[part 1 of 2: package /STELLANTIS/EPT/ASWCs]
AUTOSAR XML (schema 4-2-2)
package /STELLANTIS/EPT/ASWCs
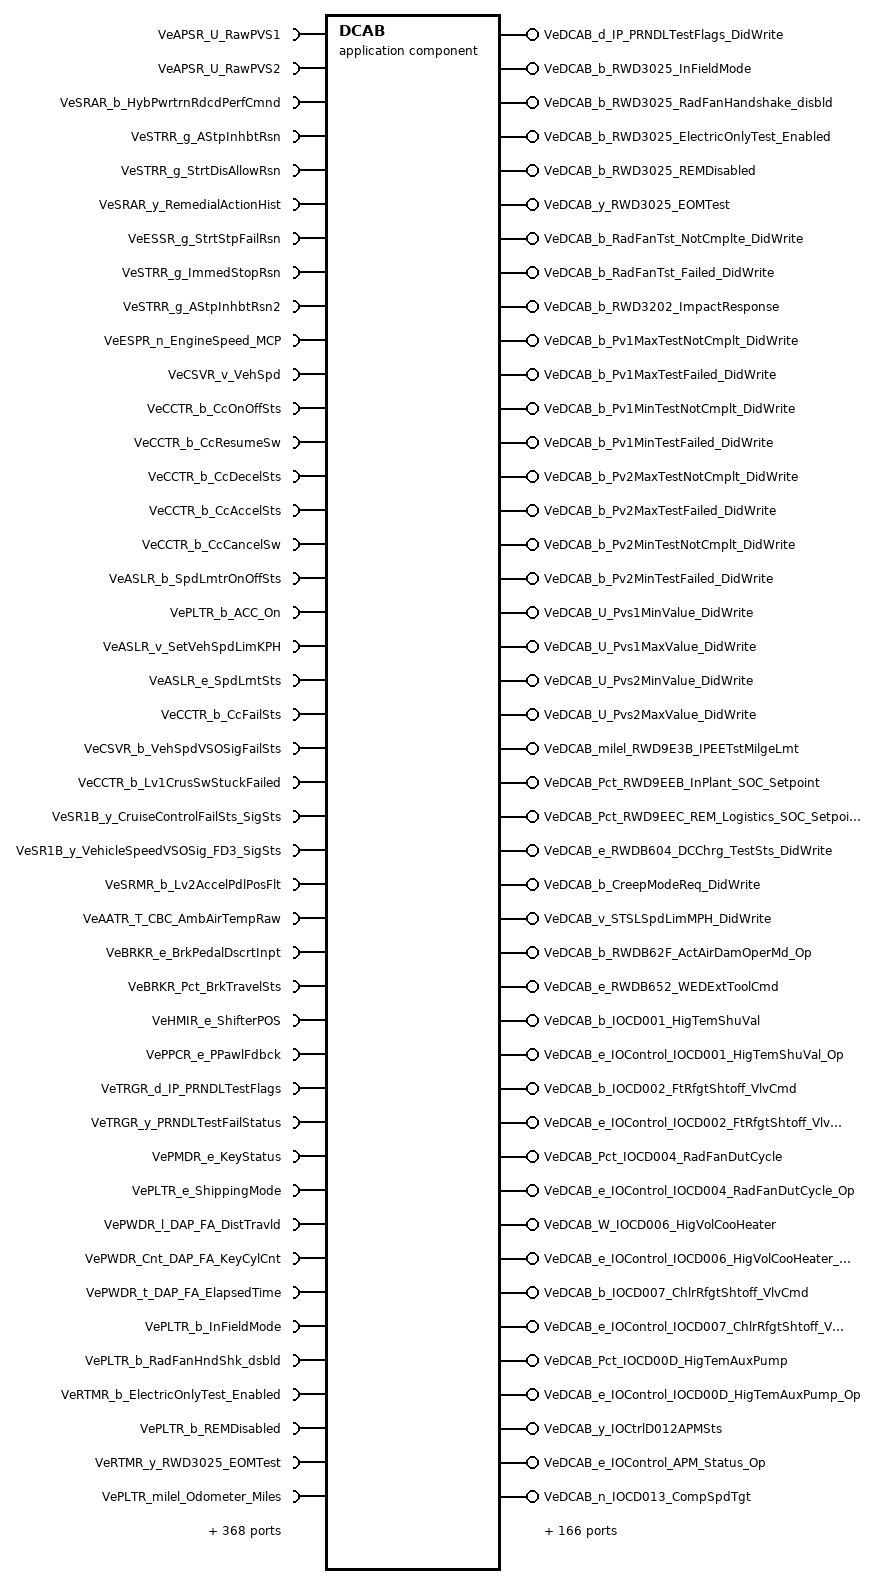
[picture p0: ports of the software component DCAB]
  application sw component type DCAB
    429 x require port:
      VeAPSR_U_RawPVS1: nonqueued-receiver-com-spec{data-element=Value, init-value=0}, required-interface=VeAPSR_U_RawPVS1
      VeAPSR_U_RawPVS2: nonqueued-receiver-com-spec{data-element=Value, init-value=0}, required-interface=VeAPSR_U_RawPVS2
      VeSRAR_b_HybPwrtrnRdcdPerfCmnd: nonqueued-receiver-com-spec{data-element=Value, init-value=0}, required-interface=VeSRAR_b_HybPwrtrnRdcdPerfCmnd
      VeSTRR_g_AStpInhbtRsn: nonqueued-receiver-com-spec{data-element=Value, init-value=0}, required-interface=VeSTRR_g_AStpInhbtRsn
      VeSTRR_g_StrtDisAllowRsn: nonqueued-receiver-com-spec{data-element=Value, init-value=0}, required-interface=VeSTRR_g_StrtDisAllowRsn
      VeSRAR_y_RemedialActionHist: nonqueued-receiver-com-spec{data-element=Value, init-value=0}, required-interface=VeSRAR_y_RemedialActionHist
      VeESSR_g_StrtStpFailRsn: nonqueued-receiver-com-spec{data-element=Value, init-value=0}, required-interface=VeESSR_g_StrtStpFailRsn
      VeSTRR_g_ImmedStopRsn: nonqueued-receiver-com-spec{data-element=Value, init-value=0}, required-interface=VeSTRR_g_ImmedStopRsn
      VeSTRR_g_AStpInhbtRsn2: nonqueued-receiver-com-spec{data-element=Value, init-value=0}, required-interface=VeSTRR_g_AStpInhbtRsn2
      VeESPR_n_EngineSpeed_MCP: nonqueued-receiver-com-spec{data-element=Value, init-value=0}, required-interface=VeESPR_n_EngineSpeed_MCP
      VeCSVR_v_VehSpd: nonqueued-receiver-com-spec{data-element=Value, init-value=0}, required-interface=VeCSVR_v_VehSpd
      VeCCTR_b_CcOnOffSts: nonqueued-receiver-com-spec{data-element=Value, init-value=0}, required-interface=VeCCTR_b_CcOnOffSts
      VeCCTR_b_CcResumeSw: nonqueued-receiver-com-spec{data-element=Value, init-value=0}, required-interface=VeCCTR_b_CcResumeSw
      VeCCTR_b_CcDecelSts: nonqueued-receiver-com-spec{data-element=Value, init-value=0}, required-interface=VeCCTR_b_CcDecelSts
      VeCCTR_b_CcAccelSts: nonqueued-receiver-com-spec{data-element=Value, init-value=0}, required-interface=VeCCTR_b_CcAccelSts
      VeCCTR_b_CcCancelSw: nonqueued-receiver-com-spec{data-element=Value, init-value=0}, required-interface=VeCCTR_b_CcCancelSw
      VeASLR_b_SpdLmtrOnOffSts: nonqueued-receiver-com-spec{data-element=Value, init-value=0}, required-interface=VeASLR_b_SpdLmtrOnOffSts
      VePLTR_b_ACC_On: nonqueued-receiver-com-spec{data-element=Value, init-value=0}, required-interface=VePLTR_b_ACC_On
      VeASLR_v_SetVehSpdLimKPH: nonqueued-receiver-com-spec{data-element=Value, init-value=0}, required-interface=VeASLR_v_SetVehSpdLimKPH
      VeASLR_e_SpdLmtSts: nonqueued-receiver-com-spec{data-element=Value, init-value=0}, required-interface=VeASLR_e_SpdLmtSts
      VeCCTR_b_CcFailSts: nonqueued-receiver-com-spec{data-element=Value, init-value=0}, required-interface=VeCCTR_b_CcFailSts
      VeCSVR_b_VehSpdVSOSigFailSts: nonqueued-receiver-com-spec{data-element=Value, init-value=0}, required-interface=VeCSVR_b_VehSpdVSOSigFailSts
      VeCCTR_b_Lv1CrusSwStuckFailed: nonqueued-receiver-com-spec{data-element=Value, init-value=0}, required-interface=VeCCTR_b_Lv1CrusSwStuckFailed
      VeSR1B_y_CruiseControlFailSts_SigSts: nonqueued-receiver-com-spec{data-element=Value, init-value=0}, required-interface=VeSR1B_y_CruiseControlFailSts_SigSts
      VeSR1B_y_VehicleSpeedVSOSig_FD3_SigSts: nonqueued-receiver-com-spec{data-element=Value, init-value=0}, required-interface=VeSR1B_y_VehicleSpeedVSOSig_FD3_SigSts
      VeSRMR_b_Lv2AccelPdlPosFlt: nonqueued-receiver-com-spec{data-element=Value, init-value=0}, required-interface=VeSRMR_b_Lv2AccelPdlPosFlt
      VeAATR_T_CBC_AmbAirTempRaw: nonqueued-receiver-com-spec{data-element=Value, init-value=0}, required-interface=VeAATR_T_CBC_AmbAirTempRaw
      VeBRKR_e_BrkPedalDscrtInpt: nonqueued-receiver-com-spec{data-element=Value, init-value=CeBRKR_e_BrkNotApplied}, required-interface=VeBRKR_e_BrkPedalDscrtInpt
      VeBRKR_Pct_BrkTravelSts: nonqueued-receiver-com-spec{data-element=Value, init-value=0}, required-interface=VeBRKR_Pct_BrkTravelSts
      VeHMIR_e_ShifterPOS: nonqueued-receiver-com-spec{data-element=Value, init-value=CeHMIR_e_ShifterPosNoSelection}, required-interface=VeHMIR_e_ShifterPOS
      VePPCR_e_PPawlFdbck: nonqueued-receiver-com-spec{data-element=Value, init-value=CePPCR_e_PPAWL_UNKNOWN_Position}, required-interface=VePPCR_e_PPawlFdbck
      VeTRGR_d_IP_PRNDLTestFlags: nonqueued-receiver-com-spec{data-element=Value, init-value=0}, required-interface=VeTRGR_d_IP_PRNDLTestFlags
      VeTRGR_y_PRNDLTestFailStatus: nonqueued-receiver-com-spec{data-element=Value, init-value=0}, required-interface=VeTRGR_y_PRNDLTestFailStatus
      VePMDR_e_KeyStatus: nonqueued-receiver-com-spec{data-element=Value, init-value=CePMDR_e_KeySt_Off}, required-interface=VePMDR_e_KeyStatus
      VePLTR_e_ShippingMode: nonqueued-receiver-com-spec{data-element=Value, init-value=CePLTR_e_ShipingMode_CUST_MD}, required-interface=VePLTR_e_ShippingMode
      VePWDR_l_DAP_FA_DistTravld: nonqueued-receiver-com-spec{data-element=Value, init-value=0}, required-interface=VePWDR_l_DAP_FA_DistTravld
      VePWDR_Cnt_DAP_FA_KeyCylCnt: nonqueued-receiver-com-spec{data-element=Value, init-value=0}, required-interface=VePWDR_Cnt_DAP_FA_KeyCylCnt
      VePWDR_t_DAP_FA_ElapsedTime: nonqueued-receiver-com-spec{data-element=Value, init-value=0}, required-interface=VePWDR_t_DAP_FA_ElapsedTime
      VePLTR_b_InFieldMode: nonqueued-receiver-com-spec{data-element=Value, init-value=0}, required-interface=VePLTR_b_InFieldMode
      VePLTR_b_RadFanHndShk_dsbld: nonqueued-receiver-com-spec{data-element=Value, init-value=0}, required-interface=VePLTR_b_RadFanHndShk_dsbld
      VeRTMR_b_ElectricOnlyTest_Enabled: nonqueued-receiver-com-spec{data-element=Value, init-value=0}, required-interface=VeRTMR_b_ElectricOnlyTest_Enabled
      VePLTR_b_REMDisabled: nonqueued-receiver-com-spec{data-element=Value, init-value=0}, required-interface=VePLTR_b_REMDisabled
      VeRTMR_y_RWD3025_EOMTest: nonqueued-receiver-com-spec{data-element=Value, init-value=0}, required-interface=VeRTMR_y_RWD3025_EOMTest
      VePLTR_milel_Odometer_Miles: nonqueued-receiver-com-spec{data-element=Value, init-value=0}, required-interface=VePLTR_milel_Odometer_Miles
      VePLTR_milel_InPlntMileageLmt_Miles: nonqueued-receiver-com-spec{data-element=Value, init-value=0}, required-interface=VePLTR_milel_InPlntMileageLmt_Miles
      VeFSCR_b_RadFanTst_NotCmplte: nonqueued-receiver-com-spec{data-element=Value, init-value=0}, required-interface=VeFSCR_b_RadFanTst_NotCmplte
      VeFSCR_b_RadFanTst_Failed: nonqueued-receiver-com-spec{data-element=Value, init-value=0}, required-interface=VeFSCR_b_RadFanTst_Failed
      VeRTMR_y_ElecOnlyTstCndtnCheck1_PID: nonqueued-receiver-com-spec{data-element=Value, init-value=0}, required-interface=VeRTMR_y_ElecOnlyTstCndtnCheck1_PID
      VeRTMR_y_ElecOnlyTstCndtnCheck2_PID: nonqueued-receiver-com-spec{data-element=Value, init-value=0}, required-interface=VeRTMR_y_ElecOnlyTstCndtnCheck2_PID
      VeRTMR_g_BSGRestartRsn: nonqueued-receiver-com-spec{data-element=Value, init-value=0}, required-interface=VeRTMR_g_BSGRestartRsn
      VeIMOR_b_BCMNoVerifResp: nonqueued-receiver-com-spec{data-element=Value, init-value=0}, required-interface=VeIMOR_b_BCMNoVerifResp
      VeIMOR_b_BCMFailedVerif: nonqueued-receiver-com-spec{data-element=Value, init-value=0}, required-interface=VeIMOR_b_BCMFailedVerif
      VeIMOR_b_BCMRespTENVerify: nonqueued-receiver-com-spec{data-element=Value, init-value=0}, required-interface=VeIMOR_b_BCMRespTENVerify
      VeIMOR_b_BCMRespUCVerify: nonqueued-receiver-com-spec{data-element=Value, init-value=0}, required-interface=VeIMOR_b_BCMRespUCVerify
      VeIMOR_b_BCMRespBadG2Verify: nonqueued-receiver-com-spec{data-element=Value, init-value=0}, required-interface=VeIMOR_b_BCMRespBadG2Verify
      VeIMOR_b_HCPNotProg: nonqueued-receiver-com-spec{data-element=Value, init-value=0}, required-interface=VeIMOR_b_HCPNotProg
      VeIMOR_b_BCMNoENQpResponse: nonqueued-receiver-com-spec{data-element=Value, init-value=0}, required-interface=VeIMOR_b_BCMNoENQpResponse
      VeIMOR_b_BCMRespTENRec: nonqueued-receiver-com-spec{data-element=Value, init-value=0}, required-interface=VeIMOR_b_BCMRespTENRec
      VeIMOR_b_BCMNoSecondRespRec: nonqueued-receiver-com-spec{data-element=Value, init-value=0}, required-interface=VeIMOR_b_BCMNoSecondRespRec
      VeIMOR_b_BCMNoPRAorMiniKeyRec: nonqueued-receiver-com-spec{data-element=Value, init-value=0}, required-interface=VeIMOR_b_BCMNoPRAorMiniKeyRec
      VeIMOR_b_BCMMiniKeyNotStoredRec: nonqueued-receiver-com-spec{data-element=Value, init-value=0}, required-interface=VeIMOR_b_BCMMiniKeyNotStoredRec
      VeIMPR_b_HighVoltageRapidShtdwnCmnd: nonqueued-receiver-com-spec{data-element=Value, init-value=0}, required-interface=VeIMPR_b_HighVoltageRapidShtdwnCmnd
      VeTMIR_T_OnBrdChrg_ClntTmpIn: nonqueued-receiver-com-spec{data-element=Value, init-value=0}, required-interface=VeTMIR_T_OnBrdChrg_ClntTmpIn
      VeTAIR_p_HghRfrgtPres: nonqueued-receiver-com-spec{data-element=Value, init-value=0}, required-interface=VeTAIR_p_HghRfrgtPres
      VeTMIR_T_PsvPmpClnt_TmpIn: nonqueued-receiver-com-spec{data-element=Value, init-value=0}, required-interface=VeTMIR_T_PsvPmpClnt_TmpIn
      VeTRIR_T_HtrCorClnt_TmpIn: nonqueued-receiver-com-spec{data-element=Value, init-value=0}, required-interface=VeTRIR_T_HtrCorClnt_TmpIn
      VeTRIR_T_HV_BatClntTmp_In: nonqueued-receiver-com-spec{data-element=Value, init-value=0}, required-interface=VeTRIR_T_HV_BatClntTmp_In
      VeTRIR_T_HV_BatClntTmpOut: nonqueued-receiver-com-spec{data-element=Value, init-value=0}, required-interface=VeTRIR_T_HV_BatClntTmpOut
      VeTAIR_n_CompSpdFdb: nonqueued-receiver-com-spec{data-element=Value, init-value=0}, required-interface=VeTAIR_n_CompSpdFdb
      VeTAIR_I_ACCElecCurr: nonqueued-receiver-com-spec{data-element=Value, init-value=0}, required-interface=VeTAIR_I_ACCElecCurr
      VeTAIR_U_CompHVInp: nonqueued-receiver-com-spec{data-element=Value, init-value=0}, required-interface=VeTAIR_U_CompHVInp
      VeTAIR_e_CompStat: nonqueued-receiver-com-spec{data-element=Value, init-value=CeTAIR_e_NormalOp}, required-interface=VeTAIR_e_CompStat
      VeTAIR_P_AC_CompElecPwr: nonqueued-receiver-com-spec{data-element=Value, init-value=0}, required-interface=VeTAIR_P_AC_CompElecPwr
      VeTAIR_T_CompBoardTemp: nonqueued-receiver-com-spec{data-element=Value, init-value=0}, required-interface=VeTAIR_T_CompBoardTemp
      VeTAIR_T_CompIGBTTemp: nonqueued-receiver-com-spec{data-element=Value, init-value=0}, required-interface=VeTAIR_T_CompIGBTTemp
      VeTAIR_e_CompFltStat: nonqueued-receiver-com-spec{data-element=Value, init-value=CeTAIR_e_CompFltSts_NoFault}, required-interface=VeTAIR_e_CompFltStat
      VeTAIR_Pct_FrWyVlv_PstnAct: nonqueued-receiver-com-spec{data-element=Value, init-value=0}, required-interface=VeTAIR_Pct_FrWyVlv_PstnAct
      VeTAIR_b_FrWyVlv_OvrVltg: nonqueued-receiver-com-spec{data-element=Value, init-value=0}, required-interface=VeTAIR_b_FrWyVlv_OvrVltg
      VeTAIR_b_FrWyVlv_UndrVltg: nonqueued-receiver-com-spec{data-element=Value, init-value=0}, required-interface=VeTAIR_b_FrWyVlv_UndrVltg
      VeTAIR_b_FrWyVlv_ThrmlWrng: nonqueued-receiver-com-spec{data-element=Value, init-value=0}, required-interface=VeTAIR_b_FrWyVlv_ThrmlWrng
      VeTAIR_b_FrWyVlv_OpnLd: nonqueued-receiver-com-spec{data-element=Value, init-value=0}, required-interface=VeTAIR_b_FrWyVlv_OpnLd
      VeTAIR_b_FrWyVlv_OvrCrnt: nonqueued-receiver-com-spec{data-element=Value, init-value=0}, required-interface=VeTAIR_b_FrWyVlv_OvrCrnt
      VeTAIR_b_FrWyVlv_MechBrk: nonqueued-receiver-com-spec{data-element=Value, init-value=0}, required-interface=VeTAIR_b_FrWyVlv_MechBrk
      VeTAIR_b_FrWyVlv_BlckPnt: nonqueued-receiver-com-spec{data-element=Value, init-value=0}, required-interface=VeTAIR_b_FrWyVlv_BlckPnt
      VeTAIR_b_FrWyVlv_Err_SNA: nonqueued-receiver-com-spec{data-element=Value, init-value=0}, required-interface=VeTAIR_b_FrWyVlv_Err_SNA
      VeTAIR_U_FrWyVlv_MtrVltg: nonqueued-receiver-com-spec{data-element=Value, init-value=0}, required-interface=VeTAIR_U_FrWyVlv_MtrVltg
      VeTAIR_e_FrWyVlv_ErrSts: nonqueued-receiver-com-spec{data-element=Value, init-value=CeTAIR_e_CPV_Status_OK}, required-interface=VeTAIR_e_FrWyVlv_ErrSts
      VeTAIR_b_FrWyVlv_RsErr: nonqueued-receiver-com-spec{data-element=Value, init-value=0}, required-interface=VeTAIR_b_FrWyVlv_RsErr
      VeTAIR_e_FrWyVlv_CalSts: nonqueued-receiver-com-spec{data-element=Value, init-value=CeTAIR_e_CPV_Calibration_Complete}, required-interface=VeTAIR_e_FrWyVlv_CalSts
      VeTAIR_Pct_EXV_PosAct: nonqueued-receiver-com-spec{data-element=Value, init-value=0}, required-interface=VeTAIR_Pct_EXV_PosAct
      VeTAIR_e_EXV_CalStat: nonqueued-receiver-com-spec{data-element=Value, init-value=CeTAIR_e_EXV_Calibration_Complete}, required-interface=VeTAIR_e_EXV_CalStat
      VeTAIR_b_EXV_CalRq: nonqueued-receiver-com-spec{data-element=Value, init-value=0}, required-interface=VeTAIR_b_EXV_CalRq
      VeTAIR_b_EXV_RspErr: nonqueued-receiver-com-spec{data-element=Value, init-value=0}, required-interface=VeTAIR_b_EXV_RspErr
      VeTAIR_e_EXV_Sts: nonqueued-receiver-com-spec{data-element=Value, init-value=CeTAIR_e_EXV_Status_OK}, required-interface=VeTAIR_e_EXV_Sts
      VeTAIR_e_EXV_Err: nonqueued-receiver-com-spec{data-element=Value, init-value=CeTAIR_e_EXV_ErrorMsg_OK}, required-interface=VeTAIR_e_EXV_Err
      VeTAIR_U_EXV_SupplyVolt: nonqueued-receiver-com-spec{data-element=Value, init-value=0}, required-interface=VeTAIR_U_EXV_SupplyVolt
      VeTAIR_p_EXV_RefPress: nonqueued-receiver-com-spec{data-element=Value, init-value=0}, required-interface=VeTAIR_p_EXV_RefPress
      VeTAIR_T_EXV_BoardTemp: nonqueued-receiver-com-spec{data-element=Value, init-value=0}, required-interface=VeTAIR_T_EXV_BoardTemp
      VeTAIR_T_EXV_RefTemp: nonqueued-receiver-com-spec{data-element=Value, init-value=0}, required-interface=VeTAIR_T_EXV_RefTemp
      VePMIR_Pct_LTPsvPumpTgtSpd: nonqueued-receiver-com-spec{data-element=Value, init-value=0}, required-interface=VePMIR_Pct_LTPsvPumpTgtSpd
      VePMPR_Pct_LTPsvPumpRPMAct: nonqueued-receiver-com-spec{data-element=Value, init-value=0}, required-interface=VePMPR_Pct_LTPsvPumpRPMAct
      VePMIR_U_LTPsvPumpVltg: nonqueued-receiver-com-spec{data-element=Value, init-value=0}, required-interface=VePMIR_U_LTPsvPumpVltg
      VePMIR_T_LTPsvPumpTemp: nonqueued-receiver-com-spec{data-element=Value, init-value=0}, required-interface=VePMIR_T_LTPsvPumpTemp
      VePMIR_I_LTPsvPumpCurrent: nonqueued-receiver-com-spec{data-element=Value, init-value=0}, required-interface=VePMIR_I_LTPsvPumpCurrent
      VePMIR_e_LTPsvPumpFailsafe: nonqueued-receiver-com-spec{data-element=Value, init-value=CePMPR_e_TFSNA_False}, required-interface=VePMIR_e_LTPsvPumpFailsafe
      VePMIR_e_LTPsvPumpLmpHM: nonqueued-receiver-com-spec{data-element=Value, init-value=CePMPR_e_FTSNA_False}, required-interface=VePMIR_e_LTPsvPumpLmpHM
      VePMIR_e_LTPsvPumpAirPresntErr: nonqueued-receiver-com-spec{data-element=Value, init-value=CePMPR_e_FTSNA_False}, required-interface=VePMIR_e_LTPsvPumpAirPresntErr
      VePMIR_e_LTPsvPumpOT: nonqueued-receiver-com-spec{data-element=Value, init-value=CePMPR_e_FTSNA_False}, required-interface=VePMIR_e_LTPsvPumpOT
      VePMIR_e_LTPsvPumpOverCurrent: nonqueued-receiver-com-spec{data-element=Value, init-value=CePMPR_e_FTSNA_False}, required-interface=VePMIR_e_LTPsvPumpOverCurrent
      VePMIR_e_LTPsvPumpDryRun: nonqueued-receiver-com-spec{data-element=Value, init-value=CePMPR_e_FTSNA_False}, required-interface=VePMIR_e_LTPsvPumpDryRun
      VePMIR_e_LTPsvPumpSuppVltErr: nonqueued-receiver-com-spec{data-element=Value, init-value=CePMPR_e_FTSNA_False}, required-interface=VePMIR_e_LTPsvPumpSuppVltErr
      VePMIR_e_LTPsvPumpDeblock: nonqueued-receiver-com-spec{data-element=Value, init-value=CePMPR_e_FTSNA_False}, required-interface=VePMIR_e_LTPsvPumpDeblock
      VePMIR_e_LTPsvPumpMntrRPM: nonqueued-receiver-com-spec{data-element=Value, init-value=CePMPR_e_TFSNA_False}, required-interface=VePMIR_e_LTPsvPumpMntrRPM
      VePMIR_e_LTPsvPumpNodeErr: nonqueued-receiver-com-spec{data-element=Value, init-value=CePMPR_e_NodeError_NoError}, required-interface=VePMIR_e_LTPsvPumpNodeErr
      VePMPR_e_LTPsvPump_PstRnSt: nonqueued-receiver-com-spec{data-element=Value, init-value=CeTMIR_e_No_AftRunRequest}, required-interface=VePMPR_e_LTPsvPump_PstRnSt
      VePMIR_b_LTPsvPumpRespErr: nonqueued-receiver-com-spec{data-element=Value, init-value=0}, required-interface=VePMIR_b_LTPsvPumpRespErr
      VePMIR_Pct_LTPsvPump2TgtSpd: nonqueued-receiver-com-spec{data-element=Value, init-value=0}, required-interface=VePMIR_Pct_LTPsvPump2TgtSpd
      VePMPR_Pct_LTPsvPump2RPMAct: nonqueued-receiver-com-spec{data-element=Value, init-value=0}, required-interface=VePMPR_Pct_LTPsvPump2RPMAct
      VePMIR_U_LTPsvPump2Vltg: nonqueued-receiver-com-spec{data-element=Value, init-value=0}, required-interface=VePMIR_U_LTPsvPump2Vltg
      VePMIR_T_LTPsvPump2Temp: nonqueued-receiver-com-spec{data-element=Value, init-value=0}, required-interface=VePMIR_T_LTPsvPump2Temp
      VePMIR_I_LTPsvPump2Current: nonqueued-receiver-com-spec{data-element=Value, init-value=0}, required-interface=VePMIR_I_LTPsvPump2Current
      VePMIR_e_LTPsvPump2Failsafe: nonqueued-receiver-com-spec{data-element=Value, init-value=CePMPR_e_TFSNA_False}, required-interface=VePMIR_e_LTPsvPump2Failsafe
      VePMIR_e_LTPsvPump2LmpHM: nonqueued-receiver-com-spec{data-element=Value, init-value=CePMPR_e_FTSNA_False}, required-interface=VePMIR_e_LTPsvPump2LmpHM
      VePMIR_e_LTPsvPump2AirPresntErr: nonqueued-receiver-com-spec{data-element=Value, init-value=CePMPR_e_FTSNA_False}, required-interface=VePMIR_e_LTPsvPump2AirPresntErr
      VePMIR_e_LTPsvPump2OT: nonqueued-receiver-com-spec{data-element=Value, init-value=CePMPR_e_FTSNA_False}, required-interface=VePMIR_e_LTPsvPump2OT
      VePMIR_e_LTPsvPump2OverCurrent: nonqueued-receiver-com-spec{data-element=Value, init-value=CePMPR_e_FTSNA_False}, required-interface=VePMIR_e_LTPsvPump2OverCurrent
      VePMIR_e_LTPsvPump2DryRun: nonqueued-receiver-com-spec{data-element=Value, init-value=CePMPR_e_FTSNA_False}, required-interface=VePMIR_e_LTPsvPump2DryRun
      VePMIR_e_LTPsvPump2SuppVltErr: nonqueued-receiver-com-spec{data-element=Value, init-value=CePMPR_e_FTSNA_False}, required-interface=VePMIR_e_LTPsvPump2SuppVltErr
      VePMIR_e_LTPsvPump2Deblock: nonqueued-receiver-com-spec{data-element=Value, init-value=CePMPR_e_FTSNA_False}, required-interface=VePMIR_e_LTPsvPump2Deblock
      VePMIR_e_LTPsvPump2MntrRPM: nonqueued-receiver-com-spec{data-element=Value, init-value=CePMPR_e_TFSNA_False}, required-interface=VePMIR_e_LTPsvPump2MntrRPM
      VePMIR_e_LTPsvPump2NodeErr: nonqueued-receiver-com-spec{data-element=Value, init-value=CePMPR_e_NodeError_NoError}, required-interface=VePMIR_e_LTPsvPump2NodeErr
      VePMPR_e_LTPsvPump2_PstRnSt: nonqueued-receiver-com-spec{data-element=Value, init-value=CeTMIR_e_No_AftRunRequest}, required-interface=VePMPR_e_LTPsvPump2_PstRnSt
      VePMIR_b_LTPsvPump2RespErr: nonqueued-receiver-com-spec{data-element=Value, init-value=0}, required-interface=VePMIR_b_LTPsvPump2RespErr
      VePMIR_T_LTActvPumpTemp: nonqueued-receiver-com-spec{data-element=Value, init-value=0}, required-interface=VePMIR_T_LTActvPumpTemp
      VePMIR_Pct_LTActvPumpTgtSpd: nonqueued-receiver-com-spec{data-element=Value, init-value=0}, required-interface=VePMIR_Pct_LTActvPumpTgtSpd
      VePMIR_Pct_LTActvPumpActSpd: nonqueued-receiver-com-spec{data-element=Value, init-value=0}, required-interface=VePMIR_Pct_LTActvPumpActSpd
      VePMIR_I_LTActvPumpCurrent: nonqueued-receiver-com-spec{data-element=Value, init-value=0}, required-interface=VePMIR_I_LTActvPumpCurrent
      VePMIR_U_LTActvPumpVlt: nonqueued-receiver-com-spec{data-element=Value, init-value=0}, required-interface=VePMIR_U_LTActvPumpVlt
      VePMIR_b_LTActvPumpRespErr: nonqueued-receiver-com-spec{data-element=Value, init-value=0}, required-interface=VePMIR_b_LTActvPumpRespErr
      VePMIR_e_LTActvPumpMntrRPM: nonqueued-receiver-com-spec{data-element=Value, init-value=CePMPR_e_FTSNA_False}, required-interface=VePMIR_e_LTActvPumpMntrRPM
      VePMIR_e_LTActvPumpLmpHM: nonqueued-receiver-com-spec{data-element=Value, init-value=CePMPR_e_FTSNA_False}, required-interface=VePMIR_e_LTActvPumpLmpHM
      VePMIR_e_LTActvPumpPstRnSt: nonqueued-receiver-com-spec{data-element=Value, init-value=CeTMIR_e_No_AftRunRequest}, required-interface=VePMIR_e_LTActvPumpPstRnSt
      VePMIR_e_LTActvPumpOverCurrent: nonqueued-receiver-com-spec{data-element=Value, init-value=CePMPR_e_FTSNA_False}, required-interface=VePMIR_e_LTActvPumpOverCurrent
      VePMIR_e_LTActvPumpOT: nonqueued-receiver-com-spec{data-element=Value, init-value=CePMPR_e_FTSNA_False}, required-interface=VePMIR_e_LTActvPumpOT
      VePMIR_e_LTActvPumpSuppVltErr: nonqueued-receiver-com-spec{data-element=Value, init-value=CePMPR_e_FTSNA_False}, required-interface=VePMIR_e_LTActvPumpSuppVltErr
      VePMIR_e_LTActvPumpNodeErr: nonqueued-receiver-com-spec{data-element=Value, init-value=CePMPR_e_NodeError_NoError}, required-interface=VePMIR_e_LTActvPumpNodeErr
      VePMIR_e_LTActvPumpDeblock: nonqueued-receiver-com-spec{data-element=Value, init-value=CePMPR_e_FTSNA_False}, required-interface=VePMIR_e_LTActvPumpDeblock
      VePMIR_e_LTActvPumpDryRun: nonqueued-receiver-com-spec{data-element=Value, init-value=CePMPR_e_FTSNA_False}, required-interface=VePMIR_e_LTActvPumpDryRun
      VePMIR_e_LTActvPumpFailsafe: nonqueued-receiver-com-spec{data-element=Value, init-value=CePMPR_e_TFSNA_False}, required-interface=VePMIR_e_LTActvPumpFailsafe
      VePMIR_e_LTAP_AirPrsntErr: nonqueued-receiver-com-spec{data-element=Value, init-value=CePMPR_e_FTSNA_False}, required-interface=VePMIR_e_LTAP_AirPrsntErr
      VePMIR_Pct_HTAuxPumpTgtSpd: nonqueued-receiver-com-spec{data-element=Value, init-value=0}, required-interface=VePMIR_Pct_HTAuxPumpTgtSpd
      VePMIR_Pct_HTAuxPumpActSpd: nonqueued-receiver-com-spec{data-element=Value, init-value=0}, required-interface=VePMIR_Pct_HTAuxPumpActSpd
      VePMIR_U_HTAuxPumpVltg: nonqueued-receiver-com-spec{data-element=Value, init-value=0}, required-interface=VePMIR_U_HTAuxPumpVltg
      VePMIR_T_HTAuxPumpTemp: nonqueued-receiver-com-spec{data-element=Value, init-value=0}, required-interface=VePMIR_T_HTAuxPumpTemp
      VePMIR_I_HTAuxPumpCurrent: nonqueued-receiver-com-spec{data-element=Value, init-value=0}, required-interface=VePMIR_I_HTAuxPumpCurrent
      VePMIR_e_HTAuxPumpFailsafe: nonqueued-receiver-com-spec{data-element=Value, init-value=CePMPR_e_TFSNA_False}, required-interface=VePMIR_e_HTAuxPumpFailsafe
      VePMIR_e_HTAuxPumpLmpHM: nonqueued-receiver-com-spec{data-element=Value, init-value=CePMPR_e_FTSNA_False}, required-interface=VePMIR_e_HTAuxPumpLmpHM
      VePMIR_e_HTAuxPumpAirPresntErr: nonqueued-receiver-com-spec{data-element=Value, init-value=CePMPR_e_FTSNA_False}, required-interface=VePMIR_e_HTAuxPumpAirPresntErr
      VePMIR_e_HTAuxPumpOT: nonqueued-receiver-com-spec{data-element=Value, init-value=CePMPR_e_FTSNA_False}, required-interface=VePMIR_e_HTAuxPumpOT
      VePMIR_e_HTAuxPumpOverCurrent: nonqueued-receiver-com-spec{data-element=Value, init-value=CePMPR_e_FTSNA_False}, required-interface=VePMIR_e_HTAuxPumpOverCurrent
      VePMIR_e_HTAuxPumpDryRun: nonqueued-receiver-com-spec{data-element=Value, init-value=CePMPR_e_FTSNA_False}, required-interface=VePMIR_e_HTAuxPumpDryRun
      VePMIR_e_HTAuxPumpSuppVltErr: nonqueued-receiver-com-spec{data-element=Value, init-value=CePMPR_e_FTSNA_False}, required-interface=VePMIR_e_HTAuxPumpSuppVltErr
      VePMIR_e_HTAuxPumpDeblock: nonqueued-receiver-com-spec{data-element=Value, init-value=CePMPR_e_FTSNA_False}, required-interface=VePMIR_e_HTAuxPumpDeblock
      VePMIR_e_HTAuxPumpMntrRPM: nonqueued-receiver-com-spec{data-element=Value, init-value=CePMPR_e_TFSNA_False}, required-interface=VePMIR_e_HTAuxPumpMntrRPM
      VePMIR_e_HTAuxPumpNodeErr: nonqueued-receiver-com-spec{data-element=Value, init-value=CePMPR_e_NodeError_NoError}, required-interface=VePMIR_e_HTAuxPumpNodeErr
      VePMIR_b_HTAuxPumpRespErr: nonqueued-receiver-com-spec{data-element=Value, init-value=0}, required-interface=VePMIR_b_HTAuxPumpRespErr
      VeTAIR_Pct_RadFanSts: nonqueued-receiver-com-spec{data-element=Value, init-value=0}, required-interface=VeTAIR_Pct_RadFanSts
      VeHTIR_e_HV_ElecClntHtr_Sts: nonqueued-receiver-com-spec{data-element=Value, init-value=CeHTIR_e_HtrSts_Off}, required-interface=VeHTIR_e_HV_ElecClntHtr_Sts
      VeHTIR_e_HVC_Htr_InterlockStat: nonqueued-receiver-com-spec{data-element=Value, init-value=CeHVTR_e_IntrlkNotSourced}, required-interface=VeHTIR_e_HVC_Htr_InterlockStat
      VeHTIR_e_HVC_HtrHighVol_Dwn: nonqueued-receiver-com-spec{data-element=Value, init-value=CeHTIR_e_Warning_False}, required-interface=VeHTIR_e_HVC_HtrHighVol_Dwn
      VeHTIR_T_HVC_HtrClntIn_Temp: nonqueued-receiver-com-spec{data-element=Value, init-value=0}, required-interface=VeHTIR_T_HVC_HtrClntIn_Temp
      VeHTIR_T_HVC_HtrClntOut_Temp: nonqueued-receiver-com-spec{data-element=Value, init-value=0}, required-interface=VeHTIR_T_HVC_HtrClntOut_Temp
      VeHTIR_I_HVC_Htr_HV_CrntAct: nonqueued-receiver-com-spec{data-element=Value, init-value=0}, required-interface=VeHTIR_I_HVC_Htr_HV_CrntAct
      VeHTIR_U_HVC_Htr_HV_VltgAct: nonqueued-receiver-com-spec{data-element=Value, init-value=0}, required-interface=VeHTIR_U_HVC_Htr_HV_VltgAct
      VeHTIR_P_HVC_HtrPwrAct: nonqueued-receiver-com-spec{data-element=Value, init-value=0}, required-interface=VeHTIR_P_HVC_HtrPwrAct
      VeHTIR_P_HVC_HtrPwrExpectd: nonqueued-receiver-com-spec{data-element=Value, init-value=0}, required-interface=VeHTIR_P_HVC_HtrPwrExpectd
      VeHTIR_b_HVC_Htr_LIN_ResErr: nonqueued-receiver-com-spec{data-element=Value, init-value=0}, required-interface=VeHTIR_b_HVC_Htr_LIN_ResErr
      VeHTIR_e_HVC_HtrIntCom_Err: nonqueued-receiver-com-spec{data-element=Value, init-value=CeHTIR_e_Warning_False}, required-interface=VeHTIR_e_HVC_HtrIntCom_Err
      VeHTIR_e_HVC_Htr_HV_OutofRng: nonqueued-receiver-com-spec{data-element=Value, init-value=CeHTIR_e_Warning_False}, required-interface=VeHTIR_e_HVC_Htr_HV_OutofRng
      VeHTIR_e_HVC_Htr_LV_OutofRng: nonqueued-receiver-com-spec{data-element=Value, init-value=CeHTIR_e_Warning_False}, required-interface=VeHTIR_e_HVC_Htr_LV_OutofRng
      VeHTIR_e_HVC_HtrClntTemp_OutofRng: nonqueued-receiver-com-spec{data-element=Value, init-value=CeHTIR_e_Warning_False}, required-interface=VeHTIR_e_HVC_HtrClntTemp_OutofRng
      VeHTIR_e_HVC_HtrSelfProtect_Actv: nonqueued-receiver-com-spec{data-element=Value, init-value=CeHTIR_e_Warning_False}, required-interface=VeHTIR_e_HVC_HtrSelfProtect_Actv
      VeHTIR_e_HVC_HtrResis_PCB_OvrTemp: nonqueued-receiver-com-spec{data-element=Value, init-value=CeHTIR_e_Warning_False}, required-interface=VeHTIR_e_HVC_HtrResis_PCB_OvrTemp
      VeHTIR_e_HVC_HtrClntIn_TempSensFlt: nonqueued-receiver-com-spec{data-element=Value, init-value=CeHTIR_e_Warning_False}, required-interface=VeHTIR_e_HVC_HtrClntIn_TempSensFlt
      VeHTIR_e_HVC_HtrClntOut_TempSensFlt: nonqueued-receiver-com-spec{data-element=Value, init-value=CeHTIR_e_Warning_False}, required-interface=VeHTIR_e_HVC_HtrClntOut_TempSensFlt
      VeHTIR_e_HVC_HtrCoreTemp_SensFlt: nonqueued-receiver-com-spec{data-element=Value, init-value=CeHTIR_e_Warning_False}, required-interface=VeHTIR_e_HVC_HtrCoreTemp_SensFlt
      VeHTIR_e_HVC_HtrDrvFlt: nonqueued-receiver-com-spec{data-element=Value, init-value=CeHTIR_e_Warning_False}, required-interface=VeHTIR_e_HVC_HtrDrvFlt
      VeHTIR_e_HVC_Htr_HV_CrntOutofRng: nonqueued-receiver-com-spec{data-element=Value, init-value=CeHTIR_e_Warning_False}, required-interface=VeHTIR_e_HVC_Htr_HV_CrntOutofRng
      VeHTIR_e_HVC_HtrProcesMemory_Flt: nonqueued-receiver-com-spec{data-element=Value, init-value=CeHTIR_e_Warning_False}, required-interface=VeHTIR_e_HVC_HtrProcesMemory_Flt
      VeHTIR_e_HVC_Htr_DCDC_VltgOutofRng: nonqueued-receiver-com-spec{data-element=Value, init-value=CeHTIR_e_Warning_False}, required-interface=VeHTIR_e_HVC_Htr_DCDC_VltgOutofRng
      VeHTIR_P_HVC_Htr4PwrExpectd: nonqueued-receiver-com-spec{data-element=Value, init-value=0}, required-interface=VeHTIR_P_HVC_Htr4PwrExpectd
      VeHTIR_P_HVC_Htr4PwrAct: nonqueued-receiver-com-spec{data-element=Value, init-value=0}, required-interface=VeHTIR_P_HVC_Htr4PwrAct
      VeHTIR_U_HVC_Htr4_HV_VltgAct: nonqueued-receiver-com-spec{data-element=Value, init-value=0}, required-interface=VeHTIR_U_HVC_Htr4_HV_VltgAct
      VeHTIR_I_HVC_Htr4_HV_CrntAct: nonqueued-receiver-com-spec{data-element=Value, init-value=0}, required-interface=VeHTIR_I_HVC_Htr4_HV_CrntAct
      VeHTIR_T_HVC_Htr4ClntIn_Temp: nonqueued-receiver-com-spec{data-element=Value, init-value=0}, required-interface=VeHTIR_T_HVC_Htr4ClntIn_Temp
      VeHTIR_T_HVC_Htr4ClntOut_Temp: nonqueued-receiver-com-spec{data-element=Value, init-value=0}, required-interface=VeHTIR_T_HVC_Htr4ClntOut_Temp
      VeHTIR_e_HVC_Htr4_DCDC_VltgOutofRng: nonqueued-receiver-com-spec{data-element=Value, init-value=CeHTIR_e_Warning_False}, required-interface=VeHTIR_e_HVC_Htr4_DCDC_VltgOutofRng
      VeHTIR_e_HVC_Htr4_HV_CrntOutofRng: nonqueued-receiver-com-spec{data-element=Value, init-value=CeHTIR_e_Warning_False}, required-interface=VeHTIR_e_HVC_Htr4_HV_CrntOutofRng
      VeHTIR_e_HVC_Htr4DrvFlt: nonqueued-receiver-com-spec{data-element=Value, init-value=CeHTIR_e_Warning_False}, required-interface=VeHTIR_e_HVC_Htr4DrvFlt
      VeHTIR_e_HVC_Htr4_LV_OutofRng: nonqueued-receiver-com-spec{data-element=Value, init-value=CeHTIR_e_Warning_False}, required-interface=VeHTIR_e_HVC_Htr4_LV_OutofRng
      VeHTIR_e_HVC_Htr4_HV_OutofRng: nonqueued-receiver-com-spec{data-element=Value, init-value=CeHTIR_e_Warning_False}, required-interface=VeHTIR_e_HVC_Htr4_HV_OutofRng
      VeHTIR_e_HVC_Htr4SelfProtect_Actv: nonqueued-receiver-com-spec{data-element=Value, init-value=CeHTIR_e_Warning_False}, required-interface=VeHTIR_e_HVC_Htr4SelfProtect_Actv
      VeHTIR_e_HVC_Htr4Resis_PCB_OvrTemp: nonqueued-receiver-com-spec{data-element=Value, init-value=CeHTIR_e_Warning_False}, required-interface=VeHTIR_e_HVC_Htr4Resis_PCB_OvrTemp
      VeHTIR_e_HVC_Htr4ClntOut_TempSensFlt: nonqueued-receiver-com-spec{data-element=Value, init-value=CeHTIR_e_Warning_False}, required-interface=VeHTIR_e_HVC_Htr4ClntOut_TempSensFlt
      VeHTIR_e_HVC_Htr4CoreTemp_SensFlt: nonqueued-receiver-com-spec{data-element=Value, init-value=CeHTIR_e_Warning_False}, required-interface=VeHTIR_e_HVC_Htr4CoreTemp_SensFlt
      VeHTIR_e_HVC_Htr4ClntIn_TempSensFlt: nonqueued-receiver-com-spec{data-element=Value, init-value=CeHTIR_e_Warning_False}, required-interface=VeHTIR_e_HVC_Htr4ClntIn_TempSensFlt
      VeHTIR_e_HVC_Htr4ClntTemp_OutofRng: nonqueued-receiver-com-spec{data-element=Value, init-value=CeHTIR_e_Warning_False}, required-interface=VeHTIR_e_HVC_Htr4ClntTemp_OutofRng
      VeHTIR_e_HV_ElecClntHtr4_Sts: nonqueued-receiver-com-spec{data-element=Value, init-value=CeHTIR_e_HtrSts_Off}, required-interface=VeHTIR_e_HV_ElecClntHtr4_Sts
      VeHTIR_e_HVC_Htr4IntCom_Err: nonqueued-receiver-com-spec{data-element=Value, init-value=CeHTIR_e_Warning_False}, required-interface=VeHTIR_e_HVC_Htr4IntCom_Err
      VeHTIR_e_HVC_Htr4ProcesMemory_Flt: nonqueued-receiver-com-spec{data-element=Value, init-value=CeHTIR_e_Warning_False}, required-interface=VeHTIR_e_HVC_Htr4ProcesMemory_Flt
      VeHTIR_b_HVC_Htr4_LIN_ResErr: nonqueued-receiver-com-spec{data-element=Value, init-value=0}, required-interface=VeHTIR_b_HVC_Htr4_LIN_ResErr
      VeHTIR_e_HV_ElecClntHtr2_Sts: nonqueued-receiver-com-spec{data-element=Value, init-value=CeHTIR_e_HtrSts_Off}, required-interface=VeHTIR_e_HV_ElecClntHtr2_Sts
      VeHTIR_I_HVC_Htr2_HV_CrntAct: nonqueued-receiver-com-spec{data-element=Value, init-value=0}, required-interface=VeHTIR_I_HVC_Htr2_HV_CrntAct
      VeHTIR_U_HVC_Htr2_HV_VltgAct: nonqueued-receiver-com-spec{data-element=Value, init-value=0}, required-interface=VeHTIR_U_HVC_Htr2_HV_VltgAct
      VeHTIR_P_HVC_Htr2PwrAct: nonqueued-receiver-com-spec{data-element=Value, init-value=0}, required-interface=VeHTIR_P_HVC_Htr2PwrAct
      VeHTIR_T_Htr2_PCBTemp: nonqueued-receiver-com-spec{data-element=Value, init-value=0}, required-interface=VeHTIR_T_Htr2_PCBTemp
      VeHTIR_T_Htr2CoreTemp: nonqueued-receiver-com-spec{data-element=Value, init-value=0}, required-interface=VeHTIR_T_Htr2CoreTemp
      VeHTIR_b_HVC_Htr2_LIN_ResErr: nonqueued-receiver-com-spec{data-element=Value, init-value=0}, required-interface=VeHTIR_b_HVC_Htr2_LIN_ResErr
      VeHTIR_e_HVC_Htr2IntCom_Err: nonqueued-receiver-com-spec{data-element=Value, init-value=CeHTIR_e_Warning_False}, required-interface=VeHTIR_e_HVC_Htr2IntCom_Err
      VeHTIR_e_HVC_Htr2_HV_OutofRng: nonqueued-receiver-com-spec{data-element=Value, init-value=CeHTIR_e_Warning_False}, required-interface=VeHTIR_e_HVC_Htr2_HV_OutofRng
      VeHTIR_e_HVC_Htr2_LV_OutofRng: nonqueued-receiver-com-spec{data-element=Value, init-value=CeHTIR_e_Warning_False}, required-interface=VeHTIR_e_HVC_Htr2_LV_OutofRng
      VeHTIR_e_HVC_Htr2TmpOvrheatg: nonqueued-receiver-com-spec{data-element=Value, init-value=CeHTIR_e_Warning_False}, required-interface=VeHTIR_e_HVC_Htr2TmpOvrheatg
      VeHTIR_e_HVC_Htr2_HV_CrntOutofRng: nonqueued-receiver-com-spec{data-element=Value, init-value=CeHTIR_e_Warning_False}, required-interface=VeHTIR_e_HVC_Htr2_HV_CrntOutofRng
      VeHTIR_e_HVC_Htr2SelfProtect_Actv: nonqueued-receiver-com-spec{data-element=Value, init-value=CeHTIR_e_Warning_False}, required-interface=VeHTIR_e_HVC_Htr2SelfProtect_Actv
      VeHTIR_e_HVC_Htr2PCBTmp_SnsrFlt: nonqueued-receiver-com-spec{data-element=Value, init-value=CeHTIR_e_Warning_False}, required-interface=VeHTIR_e_HVC_Htr2PCBTmp_SnsrFlt
      VeHTIR_e_HVC_Htr2DrvFlt: nonqueued-receiver-com-spec{data-element=Value, init-value=CeHTIR_e_Warning_False}, required-interface=VeHTIR_e_HVC_Htr2DrvFlt
      VeHTIR_e_HVC_Htr2HVCrnt_SnsrFlt: nonqueued-receiver-com-spec{data-element=Value, init-value=CeHTIR_e_Warning_False}, required-interface=VeHTIR_e_HVC_Htr2HVCrnt_SnsrFlt
      VeHTIR_e_HVC_Htr2ProcesMemory_Flt: nonqueued-receiver-com-spec{data-element=Value, init-value=CeHTIR_e_Warning_False}, required-interface=VeHTIR_e_HVC_Htr2ProcesMemory_Flt
      VeHTIR_e_HVC_Htr2CoreTemp_SensFlt: nonqueued-receiver-com-spec{data-element=Value, init-value=CeHTIR_e_Warning_False}, required-interface=VeHTIR_e_HVC_Htr2CoreTemp_SensFlt
      VeHTIR_e_HVC_Htr2Resis_PCB_OvrTemp: nonqueued-receiver-com-spec{data-element=Value, init-value=CeHTIR_e_Warning_False}, required-interface=VeHTIR_e_HVC_Htr2Resis_PCB_OvrTemp
      VeHTIR_e_HVC_Htr2Core_OvrTmp: nonqueued-receiver-com-spec{data-element=Value, init-value=CeHTIR_e_Warning_False}, required-interface=VeHTIR_e_HVC_Htr2Core_OvrTmp
      VeHMIR_e_HEV_LMP_RQ: nonqueued-receiver-com-spec{data-element=Value, init-value=CeHMIR_e_HEV_LMP_OFF}, required-interface=VeHMIR_e_HEV_LMP_RQ
      VeAPSR_b_Pv1MaxTestNotCmplt: nonqueued-receiver-com-spec{data-element=Value, init-value=0}, required-interface=VeAPSR_b_Pv1MaxTestNotCmplt
      VeAPSR_b_Pv1MaxTestFailed: nonqueued-receiver-com-spec{data-element=Value, init-value=0}, required-interface=VeAPSR_b_Pv1MaxTestFailed
      VeAPSR_b_Pv1MinTestNotCmplt: nonqueued-receiver-com-spec{data-element=Value, init-value=0}, required-interface=VeAPSR_b_Pv1MinTestNotCmplt
      VeAPSR_b_Pv1MinTestFailed: nonqueued-receiver-com-spec{data-element=Value, init-value=0}, required-interface=VeAPSR_b_Pv1MinTestFailed
      VeAPSR_b_Pv2MaxTestNotCmplt: nonqueued-receiver-com-spec{data-element=Value, init-value=0}, required-interface=VeAPSR_b_Pv2MaxTestNotCmplt
      VeAPSR_b_Pv2MaxTestFailed: nonqueued-receiver-com-spec{data-element=Value, init-value=0}, required-interface=VeAPSR_b_Pv2MaxTestFailed
      VeAPSR_b_Pv2MinTestNotCmplt: nonqueued-receiver-com-spec{data-element=Value, init-value=0}, required-interface=VeAPSR_b_Pv2MinTestNotCmplt
      VeAPSR_b_Pv2MinTestFailed: nonqueued-receiver-com-spec{data-element=Value, init-value=0}, required-interface=VeAPSR_b_Pv2MinTestFailed
      VeAPSR_U_Pvs1MinValue: nonqueued-receiver-com-spec{data-element=Value, init-value=0}, required-interface=VeAPSR_U_Pvs1MinValue
      VeAPSR_U_Pvs1MaxValue: nonqueued-receiver-com-spec{data-element=Value, init-value=0}, required-interface=VeAPSR_U_Pvs1MaxValue
      VeAPSR_U_Pvs2MinValue: nonqueued-receiver-com-spec{data-element=Value, init-value=0}, required-interface=VeAPSR_U_Pvs2MinValue
      VeAPSR_U_Pvs2MaxValue: nonqueued-receiver-com-spec{data-element=Value, init-value=0}, required-interface=VeAPSR_U_Pvs2MaxValue
      VePLTR_milel_IPEETestMileageLimit: nonqueued-receiver-com-spec{data-element=Value, init-value=0}, required-interface=VePLTR_milel_IPEETestMileageLimit
      VePLTR_Pct_InPlant_SOCSetPt: nonqueued-receiver-com-spec{data-element=Value, init-value=0}, required-interface=VePLTR_Pct_InPlant_SOCSetPt
      VePLTR_Pct_REMLogisticSOCSetPt: nonqueued-receiver-com-spec{data-element=Value, init-value=0}, required-interface=VePLTR_Pct_REMLogisticSOCSetPt
      VeRGNR_b_RollTestStatus_PID_BIT{0..6}: nonqueued-receiver-com-spec{data-element=Value, init-value=0}, required-interface=VeRGNR_b_RollTestStatus_PID_BIT{0..6}
      VeRGNR_g_RollTestOBDStatus_BIT{0..7}: nonqueued-receiver-com-spec{data-element=Value, init-value=0}, required-interface=VeRGNR_g_RollTestOBDStatus_BIT{0..7}
      VePWDR_b_HV_VoltTooLow: nonqueued-receiver-com-spec{data-element=Value, init-value=0}, required-interface=VePWDR_b_HV_VoltTooLow
      VePMDR_b_IgnRunCrnk: nonqueued-receiver-com-spec{data-element=Value, init-value=0}, required-interface=VePMDR_b_IgnRunCrnk
      VePWDR_y_DID_B524: nonqueued-receiver-com-spec{data-element=Value, init-value=0}, required-interface=VePWDR_y_DID_B524
      VeHTIR_Cnt_HVC_HtrUnlckCntr: nonqueued-receiver-com-spec{data-element=Value, init-value=0}, required-interface=VeHTIR_Cnt_HVC_HtrUnlckCntr
      VeHTRR_b_HVC_Htr_HtrClntIn_Temp_BL: nonqueued-receiver-com-spec{data-element=Value, init-value=0}, required-interface=VeHTRR_b_HVC_Htr_HtrClntIn_Temp_BL
      VeHTRR_b_HVC_Htr_CoreTemp_BL: nonqueued-receiver-com-spec{data-element=Value, init-value=0}, required-interface=VeHTRR_b_HVC_Htr_CoreTemp_BL
      VeOBCR_e_DCChrg_TestSts: nonqueued-receiver-com-spec{data-element=Value, init-value=CeOBCR_e_DCChrg_TestSts_NotInit}, required-interface=VeOBCR_e_DCChrg_TestSts
      VeOBCR_K_ChargingFailure{1..5}: nonqueued-receiver-com-spec{data-element=Value, init-value=0}, required-interface=VeOBCR_K_ChargingFailure{1..5}
      VeSRAR_b_CreepTorqMode: nonqueued-receiver-com-spec{data-element=Value, init-value=0}, required-interface=VeSRAR_b_CreepTorqMode
      VeINVR_e_MCPA_HVILSts: nonqueued-receiver-com-spec{data-element=Value, init-value=CeHVTR_e_IntrlkNotSourced}, required-interface=VeINVR_e_MCPA_HVILSts
      VeINVR_e_MCPB_HVILSts: nonqueued-receiver-com-spec{data-element=Value, init-value=CeHVTR_e_IntrlkNotSourced}, required-interface=VeINVR_e_MCPB_HVILSts
      VeIDCR_e_OBCM_HVILSts: nonqueued-receiver-com-spec{data-element=Value, init-value=CeHVTR_e_IntrlkNotSourced}, required-interface=VeIDCR_e_OBCM_HVILSts
      VeBPCR_e_HV_BatInrlkStat: nonqueued-receiver-com-spec{data-element=Value, init-value=CeHVTR_e_IntrlkNotSourced}, required-interface=VeBPCR_e_HV_BatInrlkStat
      VeBPCR_e_HVBatIntrlkIntrnlStat: nonqueued-receiver-com-spec{data-element=Value, init-value=CeBPCR_e_HVBatIntrlkSNA}, required-interface=VeBPCR_e_HVBatIntrlkIntrnlStat
      VeIDCR_I_IBS_I_Converted: nonqueued-receiver-com-spec{data-element=Value, init-value=0}, required-interface=VeIDCR_I_IBS_I_Converted
      VeTAIR_Pct_LTR_BypsVlv_ActlPstn: nonqueued-receiver-com-spec{data-element=Value, init-value=0}, required-interface=VeTAIR_Pct_LTR_BypsVlv_ActlPstn
      VeTAIR_b_LTR_BypsVlv_OvrVltg: nonqueued-receiver-com-spec{data-element=Value, init-value=0}, required-interface=VeTAIR_b_LTR_BypsVlv_OvrVltg
      VeTAIR_b_LTR_BypsVlv_UndrVltg: nonqueued-receiver-com-spec{data-element=Value, init-value=0}, required-interface=VeTAIR_b_LTR_BypsVlv_UndrVltg
      VeTAIR_b_LTR_BypsVlv_ThrmlWrng: nonqueued-receiver-com-spec{data-element=Value, init-value=0}, required-interface=VeTAIR_b_LTR_BypsVlv_ThrmlWrng
      VeTAIR_b_LTR_BypsVlv_OpnLd: nonqueued-receiver-com-spec{data-element=Value, init-value=0}, required-interface=VeTAIR_b_LTR_BypsVlv_OpnLd
      VeTAIR_b_LTR_BypsVlv_OvrCrnt: nonqueued-receiver-com-spec{data-element=Value, init-value=0}, required-interface=VeTAIR_b_LTR_BypsVlv_OvrCrnt
      VeTAIR_b_LTR_BypsVlv_MechBrk: nonqueued-receiver-com-spec{data-element=Value, init-value=0}, required-interface=VeTAIR_b_LTR_BypsVlv_MechBrk
      VeTAIR_b_LTR_BypsVlv_BlckPnt: nonqueued-receiver-com-spec{data-element=Value, init-value=0}, required-interface=VeTAIR_b_LTR_BypsVlv_BlckPnt
      VeTAIR_b_LTR_BypsVlv_Err_SNA: nonqueued-receiver-com-spec{data-element=Value, init-value=0}, required-interface=VeTAIR_b_LTR_BypsVlv_Err_SNA
      VeTAIR_U_LTR_BypsVlv_MtrVltg: nonqueued-receiver-com-spec{data-element=Value, init-value=0}, required-interface=VeTAIR_U_LTR_BypsVlv_MtrVltg
      VeTAIR_e_LTR_BypsVlv_ErrSts: nonqueued-receiver-com-spec{data-element=Value, init-value=CeTAIR_e_CPV_Status_OK}, required-interface=VeTAIR_e_LTR_BypsVlv_ErrSts
      VeTAIR_b_LTR_BypsVlv_RsErr: nonqueued-receiver-com-spec{data-element=Value, init-value=0}, required-interface=VeTAIR_b_LTR_BypsVlv_RsErr
      VeTAIR_e_LTR_BypsVlv_CalSts: nonqueued-receiver-com-spec{data-element=Value, init-value=CeTAIR_e_CPV_Calibration_Complete}, required-interface=VeTAIR_e_LTR_BypsVlv_CalSts
      VeTAIR_Pct_HTL_BypsVlv_ActlPstn: nonqueued-receiver-com-spec{data-element=Value, init-value=0}, required-interface=VeTAIR_Pct_HTL_BypsVlv_ActlPstn
      VeTAIR_b_HTL_BypsVlv_OvrVltg: nonqueued-receiver-com-spec{data-element=Value, init-value=0}, required-interface=VeTAIR_b_HTL_BypsVlv_OvrVltg
      VeTAIR_b_HTL_BypsVlv_UndrVltg: nonqueued-receiver-com-spec{data-element=Value, init-value=0}, required-interface=VeTAIR_b_HTL_BypsVlv_UndrVltg
      VeTAIR_b_HTL_BypsVlv_ThrmlWrng: nonqueued-receiver-com-spec{data-element=Value, init-value=0}, required-interface=VeTAIR_b_HTL_BypsVlv_ThrmlWrng
      VeTAIR_b_HTL_BypsVlv_OpnLd: nonqueued-receiver-com-spec{data-element=Value, init-value=0}, required-interface=VeTAIR_b_HTL_BypsVlv_OpnLd
      VeTAIR_b_HTL_BypsVlv_OvrCrnt: nonqueued-receiver-com-spec{data-element=Value, init-value=0}, required-interface=VeTAIR_b_HTL_BypsVlv_OvrCrnt
      VeTAIR_b_HTL_BypsVlv_MechBrk: nonqueued-receiver-com-spec{data-element=Value, init-value=0}, required-interface=VeTAIR_b_HTL_BypsVlv_MechBrk
      VeTAIR_b_HTL_BypsVlv_BlckPnt: nonqueued-receiver-com-spec{data-element=Value, init-value=0}, required-interface=VeTAIR_b_HTL_BypsVlv_BlckPnt
      VeTAIR_b_HTL_BypsVlv_Err_SNA: nonqueued-receiver-com-spec{data-element=Value, init-value=0}, required-interface=VeTAIR_b_HTL_BypsVlv_Err_SNA
      VeTAIR_U_HTL_BypsVlv_MtrVltg: nonqueued-receiver-com-spec{data-element=Value, init-value=0}, required-interface=VeTAIR_U_HTL_BypsVlv_MtrVltg
      VeTAIR_e_HTL_BypsVlv_ErrSts: nonqueued-receiver-com-spec{data-element=Value, init-value=CeTAIR_e_CPV_Status_OK}, required-interface=VeTAIR_e_HTL_BypsVlv_ErrSts
      VeTAIR_b_HTL_BypsVlv_RsErr: nonqueued-receiver-com-spec{data-element=Value, init-value=0}, required-interface=VeTAIR_b_HTL_BypsVlv_RsErr
      VeTAIR_e_HTL_BypsVlv_CalSts: nonqueued-receiver-com-spec{data-element=Value, init-value=CeTAIR_e_CPV_Calibration_Complete}, required-interface=VeTAIR_e_HTL_BypsVlv_CalSts
      VeASLR_v_STSLSpdLimMPH: nonqueued-receiver-com-spec{data-element=Value, init-value=0}, required-interface=VeASLR_v_STSLSpdLimMPH
      VeTAIR_e_AGS_CurrPos: nonqueued-receiver-com-spec{data-element=Value, init-value=CeFSCR_e_Open100}, required-interface=VeTAIR_e_AGS_CurrPos
      VeTAIR_e_AGS_CalibrationSts: nonqueued-receiver-com-spec{data-element=Value, init-value=CeTAIR_e_AGS_NotCalibrated}, required-interface=VeTAIR_e_AGS_CalibrationSts
      VeTAIR_b_AGS_CalibrationActv: nonqueued-receiver-com-spec{data-element=Value, init-value=0}, required-interface=VeTAIR_b_AGS_CalibrationActv
      VeTAIR_b_AGS_ErrUnderVolt: nonqueued-receiver-com-spec{data-element=Value, init-value=0}, required-interface=VeTAIR_b_AGS_ErrUnderVolt
      VeTAIR_b_AGS_ErrOverVolt: nonqueued-receiver-com-spec{data-element=Value, init-value=0}, required-interface=VeTAIR_b_AGS_ErrOverVolt
      VeTAIR_b_AGS_ErrOverTemp: nonqueued-receiver-com-spec{data-element=Value, init-value=0}, required-interface=VeTAIR_b_AGS_ErrOverTemp
      VeTAIR_b_AGS_ErrMechStuck: nonqueued-receiver-com-spec{data-element=Value, init-value=0}, required-interface=VeTAIR_b_AGS_ErrMechStuck
      VeTAIR_b_AGS_ErrMechBreak: nonqueued-receiver-com-spec{data-element=Value, init-value=0}, required-interface=VeTAIR_b_AGS_ErrMechBreak
      VeTAIR_e_AGS_ErrFdb: nonqueued-receiver-com-spec{data-element=Value, init-value=CeTAIR_e_AGS_NO_ERROR}, required-interface=VeTAIR_e_AGS_ErrFdb
      VeTAIR_b_AGS_ResErr: nonqueued-receiver-com-spec{data-element=Value, init-value=0}, required-interface=VeTAIR_b_AGS_ResErr
      VeTAIR_b_AGS_BoostSts: nonqueued-receiver-com-spec{data-element=Value, init-value=0}, required-interface=VeTAIR_b_AGS_BoostSts
      VeTAIR_e_AGS2_CurrPos: nonqueued-receiver-com-spec{data-element=Value, init-value=CeFSCR_e_Open100}, required-interface=VeTAIR_e_AGS2_CurrPos
      VeTAIR_e_AGS2_CalibrationSts: nonqueued-receiver-com-spec{data-element=Value, init-value=CeTAIR_e_AGS_NotCalibrated}, required-interface=VeTAIR_e_AGS2_CalibrationSts
      VeTAIR_b_AGS2_CalibrationActv: nonqueued-receiver-com-spec{data-element=Value, init-value=0}, required-interface=VeTAIR_b_AGS2_CalibrationActv
      VeTAIR_b_AGS2_ErrUnderVolt: nonqueued-receiver-com-spec{data-element=Value, init-value=0}, required-interface=VeTAIR_b_AGS2_ErrUnderVolt
      VeTAIR_b_AGS2_ErrOverVolt: nonqueued-receiver-com-spec{data-element=Value, init-value=0}, required-interface=VeTAIR_b_AGS2_ErrOverVolt
      VeTAIR_b_AGS2_ErrOverTemp: nonqueued-receiver-com-spec{data-element=Value, init-value=0}, required-interface=VeTAIR_b_AGS2_ErrOverTemp
      VeTAIR_b_AGS2_ErrMechStuck: nonqueued-receiver-com-spec{data-element=Value, init-value=0}, required-interface=VeTAIR_b_AGS2_ErrMechStuck
      VeTAIR_b_AGS2_ErrMechBreak: nonqueued-receiver-com-spec{data-element=Value, init-value=0}, required-interface=VeTAIR_b_AGS2_ErrMechBreak
      VeTAIR_e_AGS2_ErrFdb: nonqueued-receiver-com-spec{data-element=Value, init-value=CeTAIR_e_AGS_NO_ERROR}, required-interface=VeTAIR_e_AGS2_ErrFdb
      VeTAIR_b_AGS2_ResErr: nonqueued-receiver-com-spec{data-element=Value, init-value=0}, required-interface=VeTAIR_b_AGS2_ResErr
      VeTAIR_b_AGS2_BoostSts: nonqueued-receiver-com-spec{data-element=Value, init-value=0}, required-interface=VeTAIR_b_AGS2_BoostSts
      VePMIR_n_TransAuxPump_RPMTgt: nonqueued-receiver-com-spec{data-element=Value, init-value=0}, required-interface=VePMIR_n_TransAuxPump_RPMTgt
      VePMIR_n_AuxPumpSpdAct: nonqueued-receiver-com-spec{data-element=Value, init-value=0}, required-interface=VePMIR_n_AuxPumpSpdAct
      VePMIR_U_TransAuxPumpVoltage: nonqueued-receiver-com-spec{data-element=Value, init-value=0}, required-interface=VePMIR_U_TransAuxPumpVoltage
      VePMIR_T_TransAuxPumpTemp: nonqueued-receiver-com-spec{data-element=Value, init-value=0}, required-interface=VePMIR_T_TransAuxPumpTemp
      VePMIR_I_TransAuxPumpCurrent: nonqueued-receiver-com-spec{data-element=Value, init-value=0}, required-interface=VePMIR_I_TransAuxPumpCurrent
      VePMIR_e_TAP_ColdBiasSts: nonqueued-receiver-com-spec{data-element=Value, init-value=CeTAPR_e_TAP_FalseTrueSNA_False}, required-interface=VePMIR_e_TAP_ColdBiasSts
      VePMIR_e_TransAuxPumpMntrRPM: nonqueued-receiver-com-spec{data-element=Value, init-value=CeTAPR_e_TAP_TrueFalseSNA_False}, required-interface=VePMIR_e_TransAuxPumpMntrRPM
      VePMIR_e_TransAuxPumpLmpHM: nonqueued-receiver-com-spec{data-element=Value, init-value=CeTAPR_e_TAP_FalseTrueSNA_False}, required-interface=VePMIR_e_TransAuxPumpLmpHM
      VePMIR_e_TransAuxPumpTempError: nonqueued-receiver-com-spec{data-element=Value, init-value=CeTAPR_e_TmpErr_NO_FAULT}, required-interface=VePMIR_e_TransAuxPumpTempError
      VePMIR_e_TransAuxPumpCurrentError: nonqueued-receiver-com-spec{data-element=Value, init-value=CeTAPR_e_CrntErr_NO_FAULT}, required-interface=VePMIR_e_TransAuxPumpCurrentError
      VePMIR_e_TransAuxPumpDryRun: nonqueued-receiver-com-spec{data-element=Value, init-value=CeTAPR_e_TAP_FalseTrueSNA_False}, required-interface=VePMIR_e_TransAuxPumpDryRun
      VePMIR_e_TransAuxPumpVoltageError: nonqueued-receiver-com-spec{data-element=Value, init-value=CeTAPR_e_VltgtErr_NO_FAULT}, required-interface=VePMIR_e_TransAuxPumpVoltageError
      VePMIR_e_TransAuxPumpStallEvent: nonqueued-receiver-com-spec{data-element=Value, init-value=CeTAPR_e_StallEvnt_FALSE}, required-interface=VePMIR_e_TransAuxPumpStallEvent
      VePMIR_e_TransAuxPumpPstRnSt: nonqueued-receiver-com-spec{data-element=Value, init-value=CeTAPR_e_TAP_PostRunCmd_NoPostRun}, required-interface=VePMIR_e_TransAuxPumpPstRnSt
      VePMIR_b_TransAuxPumpRespError: nonqueued-receiver-com-spec{data-element=Value, init-value=0}, required-interface=VePMIR_b_TransAuxPumpRespError
      VePMIR_T_TransAuxPumpOilTemp: nonqueued-receiver-com-spec{data-element=Value, init-value=0}, required-interface=VePMIR_T_TransAuxPumpOilTemp
      VePMIR_y_TransAuxPmp_TAP_HW_VER: nonqueued-receiver-com-spec{data-element=Value, init-value=0}, required-interface=VePMIR_y_TransAuxPmp_TAP_HW_VER
      VePMIR_y_TransAuxPmp_TAP_SW_VER: nonqueued-receiver-com-spec{data-element=Value, init-value=0}, required-interface=VePMIR_y_TransAuxPmp_TAP_SW_VER
      VePMIR_n_TransAuxPump2TgtSpd: nonqueued-receiver-com-spec{data-element=Value, init-value=0}, required-interface=VePMIR_n_TransAuxPump2TgtSpd
      VePMIR_n_TransAuxPump2SpdAct: nonqueued-receiver-com-spec{data-element=Value, init-value=0}, required-interface=VePMIR_n_TransAuxPump2SpdAct
      VePMIR_U_TransAuxPump2Voltage: nonqueued-receiver-com-spec{data-element=Value, init-value=0}, required-interface=VePMIR_U_TransAuxPump2Voltage
      VePMIR_T_TransAuxPump2Temp: nonqueued-receiver-com-spec{data-element=Value, init-value=0}, required-interface=VePMIR_T_TransAuxPump2Temp
      VePMIR_I_TransAuxPump2Current: nonqueued-receiver-com-spec{data-element=Value, init-value=0}, required-interface=VePMIR_I_TransAuxPump2Current
      VePMIR_e_TransAuxPmp2ColdBiasSts: nonqueued-receiver-com-spec{data-element=Value, init-value=CeTAPR_e_TAP_FalseTrueSNA_False}, required-interface=VePMIR_e_TransAuxPmp2ColdBiasSts
      VePMIR_e_TransAuxPump2MntrRPM: nonqueued-receiver-com-spec{data-element=Value, init-value=CeTAPR_e_TAP_FalseTrueSNA_False}, required-interface=VePMIR_e_TransAuxPump2MntrRPM
      VePMIR_e_TransAuxPmp2LmpHM: nonqueued-receiver-com-spec{data-element=Value, init-value=CeTAPR_e_TAP_FalseTrueSNA_False}, required-interface=VePMIR_e_TransAuxPmp2LmpHM
      VePMIR_e_TransAuxPump2TempError: nonqueued-receiver-com-spec{data-element=Value, init-value=CeTAPR_e_TmpErr_NO_FAULT}, required-interface=VePMIR_e_TransAuxPump2TempError
      VePMIR_e_TransAuxPump2CurrentError: nonqueued-receiver-com-spec{data-element=Value, init-value=CeTAPR_e_CrntErr_NO_FAULT}, required-interface=VePMIR_e_TransAuxPump2CurrentError
      VePMIR_e_TransAuxPump2DryRun: nonqueued-receiver-com-spec{data-element=Value, init-value=CeTAPR_e_TAP_FalseTrueSNA_False}, required-interface=VePMIR_e_TransAuxPump2DryRun
      VePMIR_e_TransAuxPump2VoltageError: nonqueued-receiver-com-spec{data-element=Value, init-value=CeTAPR_e_VltgtErr_NO_FAULT}, required-interface=VePMIR_e_TransAuxPump2VoltageError
      VePMIR_e_TransAuxPump2StallEvent: nonqueued-receiver-com-spec{data-element=Value, init-value=CeTAPR_e_StallEvnt_FALSE}, required-interface=VePMIR_e_TransAuxPump2StallEvent
      VePMIR_e_TransAuxPump2PstRnSt: nonqueued-receiver-com-spec{data-element=Value, init-value=CeTAPR_e_TAP_PostRunCmd_NoPostRun}, required-interface=VePMIR_e_TransAuxPump2PstRnSt
      VePMIR_b_TransAuxPump2RespError: nonqueued-receiver-com-spec{data-element=Value, init-value=0}, required-interface=VePMIR_b_TransAuxPump2RespError
      VePMIR_T_TransAuxPump2OilTemp: nonqueued-receiver-com-spec{data-element=Value, init-value=0}, required-interface=VePMIR_T_TransAuxPump2OilTemp
      VePMIR_y_TransAuxPmp2_TAP_HW_VER: nonqueued-receiver-com-spec{data-element=Value, init-value=0}, required-interface=VePMIR_y_TransAuxPmp2_TAP_HW_VER
      VePMIR_y_TransAuxPmp2_TAP_SW_VER: nonqueued-receiver-com-spec{data-element=Value, init-value=0}, required-interface=VePMIR_y_TransAuxPmp2_TAP_SW_VER
      VeAADR_b_AAD_OperationModeEnbl: nonqueued-receiver-com-spec{data-element=Value, init-value=0}, required-interface=VeAADR_b_AAD_OperationModeEnbl
      VeAADR_b_AAD_ErrOverVolt: nonqueued-receiver-com-spec{data-element=Value, init-value=0}, required-interface=VeAADR_b_AAD_ErrOverVolt
      VeAADR_b_AAD_ErrUnderVolt: nonqueued-receiver-com-spec{data-element=Value, init-value=0}, required-interface=VeAADR_b_AAD_ErrUnderVolt
      VeAADR_b_AAD_CalibrationActv: nonqueued-receiver-com-spec{data-element=Value, init-value=0}, required-interface=VeAADR_b_AAD_CalibrationActv
      VeAADR_e_AAD_CalibrationSts: nonqueued-receiver-com-spec{data-element=Value, init-value=CeAADR_e_AAD_Calibrated}, required-interface=VeAADR_e_AAD_CalibrationSts
      VeAADR_Pct_AAD_CurrPos: nonqueued-receiver-com-spec{data-element=Value, init-value=0}, required-interface=VeAADR_Pct_AAD_CurrPos
      VeAADR_b_AAD_ResErr: nonqueued-receiver-com-spec{data-element=Value, init-value=0}, required-interface=VeAADR_b_AAD_ResErr
      VeAADR_b_AAD_ErrMechBreak: nonqueued-receiver-com-spec{data-element=Value, init-value=0}, required-interface=VeAADR_b_AAD_ErrMechBreak
      VeAADR_b_AAD_ErrMechStuck: nonqueued-receiver-com-spec{data-element=Value, init-value=0}, required-interface=VeAADR_b_AAD_ErrMechStuck
      VeAADR_b_AAD_ErrOverTemp: nonqueued-receiver-com-spec{data-element=Value, init-value=0}, required-interface=VeAADR_b_AAD_ErrOverTemp
      VeTAIR_Pct_EEXV_PosAct: nonqueued-receiver-com-spec{data-element=Value, init-value=0}, required-interface=VeTAIR_Pct_EEXV_PosAct
      VeTAIR_e_EEXV_CalStat: nonqueued-receiver-com-spec{data-element=Value, init-value=CeTAIR_e_EXV_Calibration_Complete}, required-interface=VeTAIR_e_EEXV_CalStat
      VeTAIR_b_EEXV_CalRq: nonqueued-receiver-com-spec{data-element=Value, init-value=0}, required-interface=VeTAIR_b_EEXV_CalRq
      VeTAIR_b_EEXV_RspErr: nonqueued-receiver-com-spec{data-element=Value, init-value=0}, required-interface=VeTAIR_b_EEXV_RspErr
      VeTAIR_e_EEXV_Sts: nonqueued-receiver-com-spec{data-element=Value, init-value=CeTAIR_e_EXV_Status_OK}, required-interface=VeTAIR_e_EEXV_Sts
      VeTAIR_e_EEXV_Err: nonqueued-receiver-com-spec{data-element=Value, init-value=CeTAIR_e_EXV_ErrorMsg_OK}, required-interface=VeTAIR_e_EEXV_Err
      VeTAIR_U_EEXV_SupplyVolt: nonqueued-receiver-com-spec{data-element=Value, init-value=0}, required-interface=VeTAIR_U_EEXV_SupplyVolt
      VeTAIR_p_EEXV_RefPress: nonqueued-receiver-com-spec{data-element=Value, init-value=0}, required-interface=VeTAIR_p_EEXV_RefPress
      VeTAIR_T_EEXV_BoardTemp: nonqueued-receiver-com-spec{data-element=Value, init-value=0}, required-interface=VeTAIR_T_EEXV_BoardTemp
      VeTAIR_T_EEXV_RefTemp: nonqueued-receiver-com-spec{data-element=Value, init-value=0}, required-interface=VeTAIR_T_EEXV_RefTemp
      VeTAIR_Pct_OEXV_PosAct: nonqueued-receiver-com-spec{data-element=Value, init-value=0}, required-interface=VeTAIR_Pct_OEXV_PosAct
      VeTAIR_e_OEXV_CalStat: nonqueued-receiver-com-spec{data-element=Value, init-value=CeTAIR_e_EXV_Calibration_Complete}, required-interface=VeTAIR_e_OEXV_CalStat
      VeTAIR_b_OEXV_CalRq: nonqueued-receiver-com-spec{data-element=Value, init-value=0}, required-interface=VeTAIR_b_OEXV_CalRq
      VeTAIR_b_OEXV_RspErr: nonqueued-receiver-com-spec{data-element=Value, init-value=0}, required-interface=VeTAIR_b_OEXV_RspErr
      VeTAIR_e_OEXV_Sts: nonqueued-receiver-com-spec{data-element=Value, init-value=CeTAIR_e_EXV_Status_OK}, required-interface=VeTAIR_e_OEXV_Sts
      VeTAIR_e_OEXV_Err: nonqueued-receiver-com-spec{data-element=Value, init-value=CeTAIR_e_EXV_ErrorMsg_OK}, required-interface=VeTAIR_e_OEXV_Err
      VeTAIR_U_OEXV_SupplyVolt: nonqueued-receiver-com-spec{data-element=Value, init-value=0}, required-interface=VeTAIR_U_OEXV_SupplyVolt
      VeTAIR_p_OEXV_RefPress: nonqueued-receiver-com-spec{data-element=Value, init-value=0}, required-interface=VeTAIR_p_OEXV_RefPress
      VeTAIR_T_OEXV_BoardTemp: nonqueued-receiver-com-spec{data-element=Value, init-value=0}, required-interface=VeTAIR_T_OEXV_BoardTemp
      VeTAIR_T_OEXV_RefTemp: nonqueued-receiver-com-spec{data-element=Value, init-value=0}, required-interface=VeTAIR_T_OEXV_RefTemp
      VeTAIB_T_OEXV_InTempSnsr: nonqueued-receiver-com-spec{data-element=Value, init-value=0}, required-interface=VeTAIB_T_OEXV_InTempSnsr
      VeADAR_e_LeftActuationStatus: nonqueued-receiver-com-spec{data-element=Value, init-value=CeADAR_e_SS_Indeterminate}, required-interface=VeADAR_e_LeftActuationStatus
      VeADAR_e_RightActuationStatus: nonqueued-receiver-com-spec{data-element=Value, init-value=CeADAR_e_SS_Indeterminate}, required-interface=VeADAR_e_RightActuationStatus
      VeADIB_Pct_WEDPosnSnsLeft: nonqueued-receiver-com-spec{data-element=Value, init-value=0}, required-interface=VeADIB_Pct_WEDPosnSnsLeft
      VeADIB_Pct_WEDPosnSnsRight: nonqueued-receiver-com-spec{data-element=Value, init-value=0}, required-interface=VeADIB_Pct_WEDPosnSnsRight
      VeADIR_e_WEDExtToolCmd: nonqueued-receiver-com-spec{data-element=Value, init-value=CeADIR_e_ECUNormalControl}, required-interface=VeADIR_e_WEDExtToolCmd
      VeRTMR_y_WEDRoutinePreConds: nonqueued-receiver-com-spec{data-element=Value, init-value=0}, required-interface=VeRTMR_y_WEDRoutinePreConds
      VeRTMR_d_WEDRoutineFailConds: nonqueued-receiver-com-spec{data-element=Value, init-value=0}, required-interface=VeRTMR_d_WEDRoutineFailConds
      VeADAR_L_LftTAPos: nonqueued-receiver-com-spec{data-element=Value, init-value=0}, required-interface=VeADAR_L_LftTAPos
      VeADAR_L_RtTAPos: nonqueued-receiver-com-spec{data-element=Value, init-value=0}, required-interface=VeADAR_L_RtTAPos
      VeBRDR_e_HV_Bat_CltLvlLo: nonqueued-receiver-com-spec{data-element=Value, init-value=CeBRDR_e_BatCltLvlNotLo}, required-interface=VeBRDR_e_HV_Bat_CltLvlLo
      VeTRIR_U_BatBotlClnt_LoLvlVolt: nonqueued-receiver-com-spec{data-element=Value, init-value=0}, required-interface=VeTRIR_U_BatBotlClnt_LoLvlVolt
      VeHSWR_b_SecHoodSts: nonqueued-receiver-com-spec{data-element=Value, init-value=0}, required-interface=VeHSWR_b_SecHoodSts
      VeHSWB_U_HoodAjarSns: nonqueued-receiver-com-spec{data-element=Value, init-value=0}, required-interface=VeHSWB_U_HoodAjarSns
      VeRCVR_e_EEXV_RtnSts: nonqueued-receiver-com-spec{data-element=Value, init-value=CeRCVR_e_EXV_Routine_In_Progress}, required-interface=VeRCVR_e_EEXV_RtnSts
      VeRCVR_e_OEXV_RtnSts: nonqueued-receiver-com-spec{data-element=Value, init-value=CeRCVR_e_EXV_Routine_In_Progress}, required-interface=VeRCVR_e_OEXV_RtnSts
      VeRCVR_e_EXV_RtnSts: nonqueued-receiver-com-spec{data-element=Value, init-value=CeRCVR_e_EXV_Routine_In_Progress}, required-interface=VeRCVR_e_EXV_RtnSts
      VeAPSR_b_PVSMaxLearnt: nonqueued-receiver-com-spec{data-element=Value, init-value=0}, required-interface=VeAPSR_b_PVSMaxLearnt
      VeAPSR_b_PVSMinLearnt: nonqueued-receiver-com-spec{data-element=Value, init-value=0}, required-interface=VeAPSR_b_PVSMinLearnt
      VeFSCR_e_AGS_RoutineControl: nonqueued-receiver-com-spec{data-element=Value, init-value=CeFSCR_e_AGS_Cal_In_Progress}, required-interface=VeFSCR_e_AGS_RoutineControl
      VeFSCR_e_AGS2_RoutineControl: nonqueued-receiver-com-spec{data-element=Value, init-value=CeFSCR_e_AGS_Cal_In_Progress}, required-interface=VeFSCR_e_AGS2_RoutineControl
      VeAADR_e_AAD_EOLCalResults: nonqueued-receiver-com-spec{data-element=Value, init-value=CeAADR_e_AAD_CalInProgress}, required-interface=VeAADR_e_AAD_EOLCalResults
      VeRCVR_e_CPV_RtnSts: nonqueued-receiver-com-spec{data-element=Value, init-value=CeRCVR_e_CPV_RoutineSts_In_Progress}, required-interface=VeRCVR_e_CPV_RtnSts
      VePWDR_b_RC1300_RoutineResults: nonqueued-receiver-com-spec{data-element=Value, init-value=0}, required-interface=VePWDR_b_RC1300_RoutineResults
      VeRCVR_e_LTR_RtnSts: nonqueued-receiver-com-spec{data-element=Value, init-value=CeRCVR_e_CPV_RoutineSts_In_Progress}, required-interface=VeRCVR_e_LTR_RtnSts
      VeRCVR_e_HTL_RtnSts: nonqueued-receiver-com-spec{data-element=Value, init-value=CeRCVR_e_CPV_RoutineSts_In_Progress}, required-interface=VeRCVR_e_HTL_RtnSts
      VeHTRR_Cnt_Htr_Unlck_RstSts: nonqueued-receiver-com-spec{data-element=Value, init-value=0}, required-interface=VeHTRR_Cnt_Htr_Unlck_RstSts
      VeRTMR_e_WED_ToothAbutResult: nonqueued-receiver-com-spec{data-element=Value, init-value=CeRTMR_e_WED_Passed}, required-interface=VeRTMR_e_WED_ToothAbutResult
      VeCITR_b_DVC_ChrgPortRq: nonqueued-receiver-com-spec{data-element=Value, init-value=0}, required-interface=VeCITR_b_DVC_ChrgPortRq
      VeCITR_b_ChrgPortLockSts: nonqueued-receiver-com-spec{data-element=Value, init-value=0}, required-interface=VeCITR_b_ChrgPortLockSts
      VeCITR_b_PortLockBCM_Cmd: nonqueued-receiver-com-spec{data-element=Value, init-value=0}, required-interface=VeCITR_b_PortLockBCM_Cmd
      VePMDB_U_BF1_SysVolt: nonqueued-receiver-com-spec{data-element=Value, init-value=0}, required-interface=VePMDB_U_BF1_SysVolt
      VePMDB_U_BF2_SysVolt: nonqueued-receiver-com-spec{data-element=Value, init-value=0}, required-interface=VePMDB_U_BF2_SysVolt
    243 x provide port:
      VeDCAB_d_IP_PRNDLTestFlags_DidWrite: nonqueued-sender-com-spec{data-element=Value, init-value=0}, provided-interface=VeDCAB_d_IP_PRNDLTestFlags_DidWrite
      VeDCAB_b_RWD3025_InFieldMode: nonqueued-sender-com-spec{data-element=Value, init-value=0}, provided-interface=VeDCAB_b_RWD3025_InFieldMode
      VeDCAB_b_RWD3025_RadFanHandshake_disbld: nonqueued-sender-com-spec{data-element=Value, init-value=0}, provided-interface=VeDCAB_b_RWD3025_RadFanHandshake_disbld
      VeDCAB_b_RWD3025_ElectricOnlyTest_Enabled: nonqueued-sender-com-spec{data-element=Value, init-value=0}, provided-interface=VeDCAB_b_RWD3025_ElectricOnlyTest_Enabled
      VeDCAB_b_RWD3025_REMDisabled: nonqueued-sender-com-spec{data-element=Value, init-value=0}, provided-interface=VeDCAB_b_RWD3025_REMDisabled
      VeDCAB_y_RWD3025_EOMTest: nonqueued-sender-com-spec{data-element=Value, init-value=0}, provided-interface=VeDCAB_y_RWD3025_EOMTest
      VeDCAB_b_RadFanTst_NotCmplte_DidWrite: nonqueued-sender-com-spec{data-element=Value, init-value=0}, provided-interface=VeDCAB_b_RadFanTst_NotCmplte_DidWrite
      VeDCAB_b_RadFanTst_Failed_DidWrite: nonqueued-sender-com-spec{data-element=Value, init-value=0}, provided-interface=VeDCAB_b_RadFanTst_Failed_DidWrite
      VeDCAB_b_RWD3202_ImpactResponse: nonqueued-sender-com-spec{data-element=Value, init-value=0}, provided-interface=VeDCAB_b_RWD3202_ImpactResponse
      VeDCAB_b_Pv1MaxTestNotCmplt_DidWrite: nonqueued-sender-com-spec{data-element=Value, init-value=0}, provided-interface=VeDCAB_b_Pv1MaxTestNotCmplt_DidWrite
      VeDCAB_b_Pv1MaxTestFailed_DidWrite: nonqueued-sender-com-spec{data-element=Value, init-value=0}, provided-interface=VeDCAB_b_Pv1MaxTestFailed_DidWrite
      VeDCAB_b_Pv1MinTestNotCmplt_DidWrite: nonqueued-sender-com-spec{data-element=Value, init-value=0}, provided-interface=VeDCAB_b_Pv1MinTestNotCmplt_DidWrite
      VeDCAB_b_Pv1MinTestFailed_DidWrite: nonqueued-sender-com-spec{data-element=Value, init-value=0}, provided-interface=VeDCAB_b_Pv1MinTestFailed_DidWrite
      VeDCAB_b_Pv2MaxTestNotCmplt_DidWrite: nonqueued-sender-com-spec{data-element=Value, init-value=0}, provided-interface=VeDCAB_b_Pv2MaxTestNotCmplt_DidWrite
      VeDCAB_b_Pv2MaxTestFailed_DidWrite: nonqueued-sender-com-spec{data-element=Value, init-value=0}, provided-interface=VeDCAB_b_Pv2MaxTestFailed_DidWrite
      VeDCAB_b_Pv2MinTestNotCmplt_DidWrite: nonqueued-sender-com-spec{data-element=Value, init-value=0}, provided-interface=VeDCAB_b_Pv2MinTestNotCmplt_DidWrite
      VeDCAB_b_Pv2MinTestFailed_DidWrite: nonqueued-sender-com-spec{data-element=Value, init-value=0}, provided-interface=VeDCAB_b_Pv2MinTestFailed_DidWrite
      VeDCAB_U_Pvs1MinValue_DidWrite: nonqueued-sender-com-spec{data-element=Value, init-value=0}, provided-interface=VeDCAB_U_Pvs1MinValue_DidWrite
      VeDCAB_U_Pvs1MaxValue_DidWrite: nonqueued-sender-com-spec{data-element=Value, init-value=0}, provided-interface=VeDCAB_U_Pvs1MaxValue_DidWrite
      VeDCAB_U_Pvs2MinValue_DidWrite: nonqueued-sender-com-spec{data-element=Value, init-value=0}, provided-interface=VeDCAB_U_Pvs2MinValue_DidWrite
      VeDCAB_U_Pvs2MaxValue_DidWrite: nonqueued-sender-com-spec{data-element=Value, init-value=0}, provided-interface=VeDCAB_U_Pvs2MaxValue_DidWrite
      VeDCAB_milel_RWD9E3B_IPEETstMilgeLmt: nonqueued-sender-com-spec{data-element=Value, init-value=0}, provided-interface=VeDCAB_milel_RWD9E3B_IPEETstMilgeLmt
      VeDCAB_Pct_RWD9EEB_InPlant_SOC_Setpoint: nonqueued-sender-com-spec{data-element=Value, init-value=0}, provided-interface=VeDCAB_Pct_RWD9EEB_InPlant_SOC_Setpoint
      VeDCAB_Pct_RWD9EEC_REM_Logistics_SOC_Setpoint: nonqueued-sender-com-spec{data-element=Value, init-value=0}, provided-interface=VeDCAB_Pct_RWD9EEC_REM_Logistics_SOC_Setpoint
      VeDCAB_e_RWDB604_DCChrg_TestSts_DidWrite: nonqueued-sender-com-spec{data-element=Value, init-value=CeOBCR_e_DCChrg_TestSts_NotInit}, provided-interface=VeDCAB_e_RWDB604_DCChrg_TestSts_DidWrite
      VeDCAB_b_CreepModeReq_DidWrite: nonqueued-sender-com-spec{data-element=Value, init-value=0}, provided-interface=VeDCAB_b_CreepModeReq_DidWrite
      VeDCAB_v_STSLSpdLimMPH_DidWrite: nonqueued-sender-com-spec{data-element=Value, init-value=0}, provided-interface=VeDCAB_v_STSLSpdLimMPH_DidWrite
      VeDCAB_b_RWDB62F_ActAirDamOperMd_Op: nonqueued-sender-com-spec{data-element=Value, init-value=0}, provided-interface=VeDCAB_b_RWDB62F_ActAirDamOperMd_Op
      VeDCAB_e_RWDB652_WEDExtToolCmd: nonqueued-sender-com-spec{data-element=Value, init-value=CeADIR_e_ECUNormalControl}, provided-interface=VeDCAB_e_RWDB652_WEDExtToolCmd
      VeDCAB_b_IOCD001_HigTemShuVal: nonqueued-sender-com-spec{data-element=Value, init-value=0}, provided-interface=VeDCAB_b_IOCD001_HigTemShuVal
      VeDCAB_e_IOControl_IOCD001_HigTemShuVal_Op: nonqueued-sender-com-spec{data-element=Value, init-value=CeDCAB_e_IO_NOP}, provided-interface=VeDCAB_e_IOControl_IOCD001_HigTemShuVal_Op
      VeDCAB_b_IOCD002_FtRfgtShtoff_VlvCmd: nonqueued-sender-com-spec{data-element=Value, init-value=0}, provided-interface=VeDCAB_b_IOCD002_FtRfgtShtoff_VlvCmd
      VeDCAB_e_IOControl_IOCD002_FtRfgtShtoff_VlvCmd_Op: nonqueued-sender-com-spec{data-element=Value, init-value=CeDCAB_e_IO_NOP}, provided-interface=VeDCAB_e_IOControl_IOCD002_FtRfgtShtoff_VlvCmd_Op
      VeDCAB_Pct_IOCD004_RadFanDutCycle: nonqueued-sender-com-spec{data-element=Value, init-value=0}, provided-interface=VeDCAB_Pct_IOCD004_RadFanDutCycle
      VeDCAB_e_IOControl_IOCD004_RadFanDutCycle_Op: nonqueued-sender-com-spec{data-element=Value, init-value=CeDCAB_e_IO_NOP}, provided-interface=VeDCAB_e_IOControl_IOCD004_RadFanDutCycle_Op
      VeDCAB_W_IOCD006_HigVolCooHeater: nonqueued-sender-com-spec{data-element=Value, init-value=0}, provided-interface=VeDCAB_W_IOCD006_HigVolCooHeater
      VeDCAB_e_IOControl_IOCD006_HigVolCooHeater_Op: nonqueued-sender-com-spec{data-element=Value, init-value=CeDCAB_e_IO_NOP}, provided-interface=VeDCAB_e_IOControl_IOCD006_HigVolCooHeater_Op
      VeDCAB_b_IOCD007_ChlrRfgtShtoff_VlvCmd: nonqueued-sender-com-spec{data-element=Value, init-value=0}, provided-interface=VeDCAB_b_IOCD007_ChlrRfgtShtoff_VlvCmd
      VeDCAB_e_IOControl_IOCD007_ChlrRfgtShtoff_VlvCmd_Op: nonqueued-sender-com-spec{data-element=Value, init-value=CeDCAB_e_IO_NOP}, provided-interface=VeDCAB_e_IOControl_IOCD007_ChlrRfgtShtoff_VlvCmd_Op
      VeDCAB_Pct_IOCD00D_HigTemAuxPump: nonqueued-sender-com-spec{data-element=Value, init-value=0}, provided-interface=VeDCAB_Pct_IOCD00D_HigTemAuxPump
      VeDCAB_e_IOControl_IOCD00D_HigTemAuxPump_Op: nonqueued-sender-com-spec{data-element=Value, init-value=CeDCAB_e_IO_NOP}, provided-interface=VeDCAB_e_IOControl_IOCD00D_HigTemAuxPump_Op
      VeDCAB_y_IOCtrlD012APMSts: nonqueued-sender-com-spec{data-element=Value, init-value=0}, provided-interface=VeDCAB_y_IOCtrlD012APMSts
      VeDCAB_e_IOControl_APM_Status_Op: nonqueued-sender-com-spec{data-element=Value, init-value=CeDCAB_e_IO_NOP}, provided-interface=VeDCAB_e_IOControl_APM_Status_Op
      VeDCAB_n_IOCD013_CompSpdTgt: nonqueued-sender-com-spec{data-element=Value, init-value=0}, provided-interface=VeDCAB_n_IOCD013_CompSpdTgt
      VeDCAB_e_IOControl_IOCD013_CompSpdTgt_Op: nonqueued-sender-com-spec{data-element=Value, init-value=CeDCAB_e_IO_NOP}, provided-interface=VeDCAB_e_IOControl_IOCD013_CompSpdTgt_Op
      VeDCAB_b_IOCtrlD014ChargePortRq: nonqueued-sender-com-spec{data-element=Value, init-value=0}, provided-interface=VeDCAB_b_IOCtrlD014ChargePortRq
      VeDCAB_e_IOControl_Charge_Port_Lock_Op: nonqueued-sender-com-spec{data-element=Value, init-value=CeDCAB_e_IO_NOP}, provided-interface=VeDCAB_e_IOControl_Charge_Port_Lock_Op
      VeDCAB_Pct_IOCD016_MtrElecCoolPmpA: nonqueued-sender-com-spec{data-element=Value, init-value=0}, provided-interface=VeDCAB_Pct_IOCD016_MtrElecCoolPmpA
      VeDCAB_e_IOControl_IOCD016_MtrElecCoolPmpA_Op: nonqueued-sender-com-spec{data-element=Value, init-value=CeDCAB_e_IO_NOP}, provided-interface=VeDCAB_e_IOControl_IOCD016_MtrElecCoolPmpA_Op
      VeDCAB_Pct_IOCD017_MtrElecCoolPmpB: nonqueued-sender-com-spec{data-element=Value, init-value=0}, provided-interface=VeDCAB_Pct_IOCD017_MtrElecCoolPmpB
      VeDCAB_e_IOControl_IOCD017_MtrElecCoolPmpB_Op: nonqueued-sender-com-spec{data-element=Value, init-value=CeDCAB_e_IO_NOP}, provided-interface=VeDCAB_e_IOControl_IOCD017_MtrElecCoolPmpB_Op
      VeDCAB_Pct_IOCD019_BatteryCoolPump: nonqueued-sender-com-spec{data-element=Value, init-value=0}, provided-interface=VeDCAB_Pct_IOCD019_BatteryCoolPump
      VeDCAB_e_IOControl_IOCD019_BatteryCoolPump_Op: nonqueued-sender-com-spec{data-element=Value, init-value=CeDCAB_e_IO_NOP}, provided-interface=VeDCAB_e_IOControl_IOCD019_BatteryCoolPump_Op
      VeDCAB_Pct_IOCDOIC_PropSysCoolCntrlValvA: nonqueued-sender-com-spec{data-element=Value, init-value=0}, provided-interface=VeDCAB_Pct_IOCDOIC_PropSysCoolCntrlValvA
      VeDCAB_e_IOControl_IOCDOIC_PropSysCoolCntrlValvA_Op: nonqueued-sender-com-spec{data-element=Value, init-value=CeDCAB_e_IO_NOP}, provided-interface=VeDCAB_e_IOControl_IOCDOIC_PropSysCoolCntrlValvA_Op
      VeDCAB_Pct_IOCD01F_ACRefrExpValvActACntrl: nonqueued-sender-com-spec{data-element=Value, init-value=0}, provided-interface=VeDCAB_Pct_IOCD01F_ACRefrExpValvActACntrl
      VeDCAB_e_IOControl_IOCD01F_ACRefrExpValvActACntrl_Op: nonqueued-sender-com-spec{data-element=Value, init-value=CeDCAB_e_IO_NOP}, provided-interface=VeDCAB_e_IOControl_IOCD01F_ACRefrExpValvActACntrl_Op
      VeDCAB_Pct_IOCD022_PropSysCoolCntrlValvB: nonqueued-sender-com-spec{data-element=Value, init-value=0}, provided-interface=VeDCAB_Pct_IOCD022_PropSysCoolCntrlValvB
      VeDCAB_e_IOControl_IOCD022_PropSysCoolCntrlValvB_Op: nonqueued-sender-com-spec{data-element=Value, init-value=CeDCAB_e_IO_NOP}, provided-interface=VeDCAB_e_IOControl_IOCD022_PropSysCoolCntrlValvB_Op
      VeDCAB_Pct_IOCD023_PropSysCoolCntrlValvC: nonqueued-sender-com-spec{data-element=Value, init-value=0}, provided-interface=VeDCAB_Pct_IOCD023_PropSysCoolCntrlValvC
      VeDCAB_e_IOControl_IOCD023_PropSysCoolCntrlValvC_Op: nonqueued-sender-com-spec{data-element=Value, init-value=CeDCAB_e_IO_NOP}, provided-interface=VeDCAB_e_IOControl_IOCD023_PropSysCoolCntrlValvC_Op
      VeDCAB_e_IOCD025_AGS_PstnCmnd: nonqueued-sender-com-spec{data-element=Value, init-value=CeFSCR_e_Open100}, provided-interface=VeDCAB_e_IOCD025_AGS_PstnCmnd
      VeDCAB_e_IOControl_IOCD025_AGS_PstnCmnd_Op: nonqueued-sender-com-spec{data-element=Value, init-value=CeDCAB_e_IO_NOP}, provided-interface=VeDCAB_e_IOControl_IOCD025_AGS_PstnCmnd_Op
      VeDCAB_e_IOCD026_AGS2_PstnCmnd: nonqueued-sender-com-spec{data-element=Value, init-value=CeFSCR_e_Open100}, provided-interface=VeDCAB_e_IOCD026_AGS2_PstnCmnd
      VeDCAB_e_IOControl_IOCD026_AGS2_PstnCmnd_Op: nonqueued-sender-com-spec{data-element=Value, init-value=CeDCAB_e_IO_NOP}, provided-interface=VeDCAB_e_IOControl_IOCD026_AGS2_PstnCmnd_Op
      VeDCAB_n_IOCD027_PowOilPumACon_Pump_Speed: nonqueued-sender-com-spec{data-element=Value, init-value=0}, provided-interface=VeDCAB_n_IOCD027_PowOilPumACon_Pump_Speed
      VeDCAB_e_IOControl_IOCD027_PowOilPumACon_Pump_Speed_Op: nonqueued-sender-com-spec{data-element=Value, init-value=CeDCAB_e_IO_NOP}, provided-interface=VeDCAB_e_IOControl_IOCD027_PowOilPumACon_Pump_Speed_Op
      VeDCAB_n_IOCD028_PowOilPumBCon_Pump_Speed: nonqueued-sender-com-spec{data-element=Value, init-value=0}, provided-interface=VeDCAB_n_IOCD028_PowOilPumBCon_Pump_Speed
      VeDCAB_e_IOControl_IOCD028_PowOilPumBCon_Pump_Speed_Op: nonqueued-sender-com-spec{data-element=Value, init-value=CeDCAB_e_IO_NOP}, provided-interface=VeDCAB_e_IOControl_IOCD028_PowOilPumBCon_Pump_Speed_Op
      VeDCAB_Pct_IOCD031_ACRefrExpValvActACntrl: nonqueued-sender-com-spec{data-element=Value, init-value=0}, provided-interface=VeDCAB_Pct_IOCD031_ACRefrExpValvActACntrl
      VeDCAB_e_IOControl_IOCD031_ACRefrExpValvActACntrl_Op: nonqueued-sender-com-spec{data-element=Value, init-value=CeDCAB_e_IO_NOP}, provided-interface=VeDCAB_e_IOControl_IOCD031_ACRefrExpValvActACntrl_Op
      VeDCAB_Pct_IOCD032_ACRefrExpValvActCCntrl: nonqueued-sender-com-spec{data-element=Value, init-value=0}, provided-interface=VeDCAB_Pct_IOCD032_ACRefrExpValvActCCntrl
      VeDCAB_e_IOControl_IOCD032_ACRefrExpValvActCCntrl_Op: nonqueued-sender-com-spec{data-element=Value, init-value=CeDCAB_e_IO_NOP}, provided-interface=VeDCAB_e_IOControl_IOCD032_ACRefrExpValvActCCntrl_Op
      VeDCAB_Pct_IOCD033_ACRefrExpValvActDCntrl: nonqueued-sender-com-spec{data-element=Value, init-value=0}, provided-interface=VeDCAB_Pct_IOCD033_ACRefrExpValvActDCntrl
      VeDCAB_e_IOControl_IOCD033_ACRefrExpValvActDCntrl_Op: nonqueued-sender-com-spec{data-element=Value, init-value=CeDCAB_e_IO_NOP}, provided-interface=VeDCAB_e_IOControl_IOCD033_ACRefrExpValvActDCntrl_Op
      VeDCAB_e_Routine_RC130C_AccPedLea_Op: nonqueued-sender-com-spec{data-element=Value, init-value=CeDCAB_e_Routine_NOP}, provided-interface=VeDCAB_e_Routine_RC130C_AccPedLea_Op
      VeDCAB_e_Routine_RC1332_ACRefExpValActCCal_Op: nonqueued-sender-com-spec{data-element=Value, init-value=CeDCAB_e_Routine_NOP}, provided-interface=VeDCAB_e_Routine_RC1332_ACRefExpValActCCal_Op
      VeDCAB_e_Routine_RC1333_ACRefExpValActDCal_Op: nonqueued-sender-com-spec{data-element=Value, init-value=CeDCAB_e_Routine_NOP}, provided-interface=VeDCAB_e_Routine_RC1333_ACRefExpValActDCal_Op
      VeDCAB_e_Routine_RC130D_EXVValCal_Op: nonqueued-sender-com-spec{data-element=Value, init-value=CeDCAB_e_Routine_NOP}, provided-interface=VeDCAB_e_Routine_RC130D_EXVValCal_Op
      VeDCAB_e_Routine_RC1313_ActGriShu1Cal_Op: nonqueued-sender-com-spec{data-element=Value, init-value=CeDCAB_e_Routine_NOP}, provided-interface=VeDCAB_e_Routine_RC1313_ActGriShu1Cal_Op
      VeDCAB_e_Routine_RC1314_ActGriShu2Cal_Op: nonqueued-sender-com-spec{data-element=Value, init-value=CeDCAB_e_Routine_NOP}, provided-interface=VeDCAB_e_Routine_RC1314_ActGriShu2Cal_Op
      VeDCAB_e_Routine_RC1330_ActAirDamCal_Op: nonqueued-sender-com-spec{data-element=Value, init-value=CeDCAB_e_Routine_NOP}, provided-interface=VeDCAB_e_Routine_RC1330_ActAirDamCal_Op
      VeDCAB_e_Routine_RC1309_CPV_ClbrtnRtn_Op: nonqueued-sender-com-spec{data-element=Value, init-value=CeDCAB_e_Routine_NOP}, provided-interface=VeDCAB_e_Routine_RC1309_CPV_ClbrtnRtn_Op
      VeDCAB_e_Routine_RC1300_HVOpnCblReset_Op: nonqueued-sender-com-spec{data-element=Value, init-value=CeDCAB_e_Routine_NOP}, provided-interface=VeDCAB_e_Routine_RC1300_HVOpnCblReset_Op
      VeDCAB_e_Routine_RC130E_LTR_ClbrtnRtn_Op: nonqueued-sender-com-spec{data-element=Value, init-value=CeDCAB_e_Routine_NOP}, provided-interface=VeDCAB_e_Routine_RC130E_LTR_ClbrtnRtn_Op
      VeDCAB_e_Routine_RC130F_HTL_ClbrtnRtn_Op: nonqueued-sender-com-spec{data-element=Value, init-value=CeDCAB_e_Routine_NOP}, provided-interface=VeDCAB_e_Routine_RC130F_HTL_ClbrtnRtn_Op
      VeDCAB_e_Routine_RC1303_CabOveLoc_Op: nonqueued-sender-com-spec{data-element=Value, init-value=CeDCAB_e_Routine_NOP}, provided-interface=VeDCAB_e_Routine_RC1303_CabOveLoc_Op
      VeDCAB_e_Routine_RC1336_ToothAbutmentLearning_Op: nonqueued-sender-com-spec{data-element=Value, init-value=CeDCAB_e_Routine_NOP}, provided-interface=VeDCAB_e_Routine_RC1336_ToothAbutmentLearning_Op
      VeDCAB_e_Routine_RC130B_OBD2PIDsReset_Op: nonqueued-sender-com-spec{data-element=Value, init-value=CeDCAB_e_Routine_NOP}, provided-interface=VeDCAB_e_Routine_RC130B_OBD2PIDsReset_Op
      VeDCAB_W_IOCD01A_BatCooHea: nonqueued-sender-com-spec{data-element=Value, init-value=0}, provided-interface=VeDCAB_W_IOCD01A_BatCooHea
      VeDCAB_e_IOControl_IOCD01A_BatCooHea_Op: nonqueued-sender-com-spec{data-element=Value, init-value=CeDCAB_e_IO_NOP}, provided-interface=VeDCAB_e_IOControl_IOCD01A_BatCooHea_Op
      VeDCAB_Pct_IOCD01E_AirHeaCon: nonqueued-sender-com-spec{data-element=Value, init-value=0}, provided-interface=VeDCAB_Pct_IOCD01E_AirHeaCon
      VeDCAB_e_IOControl_IOCD01E_AirHeaCon_Op: nonqueued-sender-com-spec{data-element=Value, init-value=CeDCAB_e_IO_NOP}, provided-interface=VeDCAB_e_IOControl_IOCD01E_AirHeaCon_Op
      VeDCAB_e_IOCD030_ActAirDamCon: nonqueued-sender-com-spec{data-element=Value, init-value=CeAADR_e_SNA}, provided-interface=VeDCAB_e_IOCD030_ActAirDamCon
      VeDCAB_e_IOControl_IOCD030_ActAirDamCon_Op: nonqueued-sender-com-spec{data-element=Value, init-value=CeDCAB_e_IO_NOP}, provided-interface=VeDCAB_e_IOControl_IOCD030_ActAirDamCon_Op
      VeDCAB_Pct_IOCD043_PWMElectricOilPump: nonqueued-sender-com-spec{data-element=Value, init-value=0}, provided-interface=VeDCAB_Pct_IOCD043_PWMElectricOilPump
      VeDCAB_e_IOControl_IOCD043_PWMElectricOilPump_Op: nonqueued-sender-com-spec{data-element=Value, init-value=CeDCAB_e_IO_NOP}, provided-interface=VeDCAB_e_IOControl_IOCD043_PWMElectricOilPump_Op
      DataServices_IOCD001_Data: provided-interface=DataServices_IOCD001_Data
        provided-com-specs:
          operation=ReturnControlToECU, queue-length=1
          operation=ReadData, queue-length=1
          operation=ShortTermAdjustment, queue-length=1
      DataServices_IOCD002_Data: provided-interface=DataServices_IOCD002_Data
        provided-com-specs:
          operation=ReturnControlToECU, queue-length=1
          operation=ReadData, queue-length=1
          operation=ShortTermAdjustment, queue-length=1
      DataServices_IOCD004_Data: provided-interface=DataServices_IOCD004_Data
        provided-com-specs:
          operation=ReturnControlToECU, queue-length=1
          operation=ReadData, queue-length=1
          operation=ShortTermAdjustment, queue-length=1
      DataServices_IOCD006_Data: provided-interface=DataServices_IOCD006_Data
        provided-com-specs:
          operation=ReturnControlToECU, queue-length=1
          operation=ResetToDefault, queue-length=1
          operation=ReadData, queue-length=1
          operation=ShortTermAdjustment, queue-length=1
      DataServices_IOCD007_Data: provided-interface=DataServices_IOCD007_Data
        provided-com-specs:
          operation=ReturnControlToECU, queue-length=1
          operation=ReadData, queue-length=1
          operation=ShortTermAdjustment, queue-length=1
      DataServices_IOCD00D_Data: provided-interface=DataServices_IOCD00D_Data
        provided-com-specs:
          operation=ReturnControlToECU, queue-length=1
          operation=ResetToDefault, queue-length=1
          operation=ReadData, queue-length=1
          operation=ShortTermAdjustment, queue-length=1
      DataServices_IOCD012_Data: provided-interface=DataServices_IOCD012_Data
        provided-com-specs:
          operation=ReturnControlToECU, queue-length=1
          operation=ReadData, queue-length=1
          operation=ShortTermAdjustment, queue-length=1
      DataServices_IOCD013_Data: provided-interface=DataServices_IOCD013_Data
        provided-com-specs:
          operation=ReturnControlToECU, queue-length=1
          operation=ResetToDefault, queue-length=1
          operation=ReadData, queue-length=1
          operation=ShortTermAdjustment, queue-length=1
      DataServices_IOCD014_Data: provided-interface=DataServices_IOCD014_Data
        provided-com-specs:
          operation=ReturnControlToECU, queue-length=1
          operation=ResetToDefault, queue-length=1
          operation=ReadData, queue-length=1
          operation=ShortTermAdjustment, queue-length=1
      DataServices_IOCD016_Data: provided-interface=DataServices_IOCD016_Data
        provided-com-specs:
          operation=ReturnControlToECU, queue-length=1
          operation=ReadData, queue-length=1
          operation=ShortTermAdjustment, queue-length=1
      DataServices_IOCD017_Data: provided-interface=DataServices_IOCD017_Data
        provided-com-specs:
          operation=ReturnControlToECU, queue-length=1
          operation=ResetToDefault, queue-length=1
          operation=ReadData, queue-length=1
          operation=ShortTermAdjustment, queue-length=1
      DataServices_IOCD019_Data: provided-interface=DataServices_IOCD019_Data
        provided-com-specs:
          operation=ReturnControlToECU, queue-length=1
          operation=ResetToDefault, queue-length=1
          operation=ReadData, queue-length=1
          operation=ShortTermAdjustment, queue-length=1
      DataServices_IOCD01A_Data: provided-interface=DataServices_IOCD01A_Data
        provided-com-specs:
          operation=ReturnControlToECU, queue-length=1
          operation=ResetToDefault, queue-length=1
          operation=ReadData, queue-length=1
          operation=ShortTermAdjustment, queue-length=1
      DataServices_IOCD01C_Data: provided-interface=DataServices_IOCD01C_Data
        provided-com-specs:
          operation=ReturnControlToECU, queue-length=1
          operation=ReadData, queue-length=1
          operation=ShortTermAdjustment, queue-length=1
      DataServices_IOCD01E_Data: provided-interface=DataServices_IOCD01E_Data
        provided-com-specs:
          operation=ReturnControlToECU, queue-length=1
          operation=ReadData, queue-length=1
          operation=ShortTermAdjustment, queue-length=1
      DataServices_IOCD01F_Data: provided-interface=DataServices_IOCD01F_Data
        provided-com-specs:
          operation=ReturnControlToECU, queue-length=1
          operation=ResetToDefault, queue-length=1
          operation=ReadData, queue-length=1
          operation=ShortTermAdjustment, queue-length=1
      DataServices_IOCD022_Data: provided-interface=DataServices_IOCD022_Data
        provided-com-specs:
          operation=ReturnControlToECU, queue-length=1
          operation=ReadData, queue-length=1
          operation=ShortTermAdjustment, queue-length=1
      DataServices_IOCD023_Data: provided-interface=DataServices_IOCD023_Data
        provided-com-specs:
          operation=ReturnControlToECU, queue-length=1
          operation=ReadData, queue-length=1
          operation=ShortTermAdjustment, queue-length=1
      DataServices_IOCD025_Data: provided-interface=DataServices_IOCD025_Data
        provided-com-specs:
          operation=ReturnControlToECU, queue-length=1
          operation=ReadData, queue-length=1
          operation=ShortTermAdjustment, queue-length=1
      DataServices_IOCD026_Data: provided-interface=DataServices_IOCD026_Data
        provided-com-specs:
          operation=ReturnControlToECU, queue-length=1
          operation=ReadData, queue-length=1
          operation=ShortTermAdjustment, queue-length=1
      DataServices_IOCD027_Data: provided-interface=DataServices_IOCD027_Data
        provided-com-specs:
          operation=ReturnControlToECU, queue-length=1
          operation=ReadData, queue-length=1
          operation=ShortTermAdjustment, queue-length=1
      DataServices_IOCD028_Data: provided-interface=DataServices_IOCD028_Data
        provided-com-specs:
          operation=FreezeCurrentState, queue-length=1
          operation=ReturnControlToECU, queue-length=1
          operation=ReadData, queue-length=1
          operation=ShortTermAdjustment, queue-length=1
      DataServices_IOCD030_Data: provided-interface=DataServices_IOCD030_Data
        provided-com-specs:
          operation=ReturnControlToECU, queue-length=1
          operation=ReadData, queue-length=1
          operation=ShortTermAdjustment, queue-length=1
      DataServices_IOCD031_Data: provided-interface=DataServices_IOCD031_Data
        provided-com-specs:
          operation=ReturnControlToECU, queue-length=1
          operation=ReadData, queue-length=1
          operation=ShortTermAdjustment, queue-length=1
      DataServices_IOCD032_Data: provided-interface=DataServices_IOCD032_Data
        provided-com-specs:
          operation=ReturnControlToECU, queue-length=1
          operation=ResetToDefault, queue-length=1
          operation=ReadData, queue-length=1
          operation=ShortTermAdjustment, queue-length=1
      DataServices_IOCD033_Data: provided-interface=DataServices_IOCD033_Data
        provided-com-specs:
          operation=ReturnControlToECU, queue-length=1
          operation=ResetToDefault, queue-length=1
          operation=ReadData, queue-length=1
          operation=ShortTermAdjustment, queue-length=1
      DataServices_IOCD043_Data: provided-interface=DataServices_IOCD043_Data
        provided-com-specs:
          operation=ReturnControlToECU, queue-length=1
          operation=ReadData, queue-length=1
          operation=ShortTermAdjustment, queue-length=1
      DataServices_RD0306_Data: server-com-spec{operation=ReadData, queue-length=1}, provided-interface=DataServices_RD0306_Data
      DataServices_RD0307_Data: server-com-spec{operation=ReadData, queue-length=1}, provided-interface=DataServices_RD0307_Data
      DataServices_RD0507_Data: server-com-spec{operation=ReadData, queue-length=1}, provided-interface=DataServices_RD0507_Data
      DataServices_RD{0800..0805}_Data: server-com-spec{operation=ReadData, queue-length=1}, provided-interface=DataServices_RD{0800..0805}_Data
      DataServices_RD1000_Data: server-com-spec{operation=ReadData, queue-length=1}, provided-interface=DataServices_RD1000_Data
      DataServices_RD1002_Data: server-com-spec{operation=ReadData, queue-length=1}, provided-interface=DataServices_RD1002_Data
      DataServices_RD1004_Data: server-com-spec{operation=ReadData, queue-length=1}, provided-interface=DataServices_RD1004_Data
      DataServices_RD1927_Data: server-com-spec{operation=ReadData, queue-length=1}, provided-interface=DataServices_RD1927_Data
      DataServices_RD19B{0..3}_Data: server-com-spec{operation=ReadData, queue-length=1}, provided-interface=DataServices_RD19B{0..3}_Data
      DataServices_RD201E_Data: server-com-spec{operation=ReadData, queue-length=1}, provided-interface=DataServices_RD201E_Data
      DataServices_RD2500_Data: server-com-spec{operation=ReadData, queue-length=1}, provided-interface=DataServices_RD2500_Data
      DataServices_RD2505_Data: server-com-spec{operation=ReadData, queue-length=1}, provided-interface=DataServices_RD2505_Data
      DataServices_RD2518_Data: server-com-spec{operation=ReadData, queue-length=1}, provided-interface=DataServices_RD2518_Data
      DataServices_RD2801_Data: server-com-spec{operation=ReadData, queue-length=1}, provided-interface=DataServices_RD2801_Data
      DataServices_RD2802_Data: server-com-spec{operation=ReadData, queue-length=1}, provided-interface=DataServices_RD2802_Data
      DataServices_RD2949_Data: server-com-spec{operation=ReadData, queue-length=1}, provided-interface=DataServices_RD2949_Data
      DataServices_RD3004_Data: server-com-spec{operation=ReadData, queue-length=1}, provided-interface=DataServices_RD3004_Data
      DataServices_RD3027_Data: server-com-spec{operation=ReadData, queue-length=1}, provided-interface=DataServices_RD3027_Data
      DataServices_RD3028_Data: server-com-spec{operation=ReadData, queue-length=1}, provided-interface=DataServices_RD3028_Data
      DataServices_RD3035_Data: server-com-spec{operation=ReadData, queue-length=1}, provided-interface=DataServices_RD3035_Data
      DataServices_RD3036_Data: server-com-spec{operation=ReadData, queue-length=1}, provided-interface=DataServices_RD3036_Data
      DataServices_RD3200_Data: server-com-spec{operation=ReadData, queue-length=1}, provided-interface=DataServices_RD3200_Data
      DataServices_RD{4000..4002}_Data: server-com-spec{operation=ReadData, queue-length=1}, provided-interface=DataServices_RD{4000..4002}_Data
      DataServices_RD4004_Data: server-com-spec{operation=ReadData, queue-length=1}, provided-interface=DataServices_RD4004_Data
      DataServices_RD400A_Data: server-com-spec{operation=ReadData, queue-length=1}, provided-interface=DataServices_RD400A_Data
      DataServices_RD400C_Data: server-com-spec{operation=ReadData, queue-length=1}, provided-interface=DataServices_RD400C_Data
      DataServices_RD{4010..4016}_Data: server-com-spec{operation=ReadData, queue-length=1}, provided-interface=DataServices_RD{4010..4016}_Data
      DataServices_RD401C_Data: server-com-spec{operation=ReadData, queue-length=1}, provided-interface=DataServices_RD401C_Data
      DataServices_RD401F_Data: server-com-spec{operation=ReadData, queue-length=1}, provided-interface=DataServices_RD401F_Data
      DataServices_RD4021_Data: server-com-spec{operation=ReadData, queue-length=1}, provided-interface=DataServices_RD4021_Data
      DataServices_RD4036_Data: server-com-spec{operation=ReadData, queue-length=1}, provided-interface=DataServices_RD4036_Data
      DataServices_RD4037_Data: server-com-spec{operation=ReadData, queue-length=1}, provided-interface=DataServices_RD4037_Data
      DataServices_RD4039_Data: server-com-spec{operation=ReadData, queue-length=1}, provided-interface=DataServices_RD4039_Data
      DataServices_RD403D_Data: server-com-spec{operation=ReadData, queue-length=1}, provided-interface=DataServices_RD403D_Data
      DataServices_RD4040_Data: server-com-spec{operation=ReadData, queue-length=1}, provided-interface=DataServices_RD4040_Data
      DataServices_RD{4050..4053}_Data: server-com-spec{operation=ReadData, queue-length=1}, provided-interface=DataServices_RD{4050..4053}_Data
      DataServices_RD4055_Data: server-com-spec{operation=ReadData, queue-length=1}, provided-interface=DataServices_RD4055_Data
      DataServices_RD4056_Data: server-com-spec{operation=ReadData, queue-length=1}, provided-interface=DataServices_RD4056_Data
      DataServices_RD6360_Data: server-com-spec{operation=ReadData, queue-length=1}, provided-interface=DataServices_RD6360_Data
      DataServices_RD9EED_Data: server-com-spec{operation=ReadData, queue-length=1}, provided-interface=DataServices_RD9EED_Data
      DataServices_RDB000_Data: server-com-spec{operation=ReadData, queue-length=1}, provided-interface=DataServices_RDB000_Data
      DataServices_RDB523_Data: server-com-spec{operation=ReadData, queue-length=1}, provided-interface=DataServices_RDB523_Data
      DataServices_RDB524_Data: server-com-spec{operation=ReadData, queue-length=1}, provided-interface=DataServices_RDB524_Data
      DataServices_RDB526_Data: server-com-spec{operation=ReadData, queue-length=1}, provided-interface=DataServices_RDB526_Data
      DataServices_RDB605_Data: server-com-spec{operation=ReadData, queue-length=1}, provided-interface=DataServices_RDB605_Data
      DataServices_RDB{612..614}_Data: server-com-spec{operation=ReadData, queue-length=1}, provided-interface=DataServices_RDB{612..614}_Data
      DataServices_RDB616_Data: server-com-spec{operation=ReadData, queue-length=1}, provided-interface=DataServices_RDB616_Data
      DataServices_RDB621_Data: server-com-spec{operation=ReadData, queue-length=1}, provided-interface=DataServices_RDB621_Data
      DataServices_RDB622_Data: server-com-spec{operation=ReadData, queue-length=1}, provided-interface=DataServices_RDB622_Data
      DataServices_RDB{626..629}_Data: server-com-spec{operation=ReadData, queue-length=1}, provided-interface=DataServices_RDB{626..629}_Data
      DataServices_RDB62A_Data: server-com-spec{operation=ReadData, queue-length=1}, provided-interface=DataServices_RDB62A_Data
      DataServices_RDB62B_Data: server-com-spec{operation=ReadData, queue-length=1}, provided-interface=DataServices_RDB62B_Data
      DataServices_RDB{630..634}_Data: server-com-spec{operation=ReadData, queue-length=1}, provided-interface=DataServices_RDB{630..634}_Data
      DataServices_RDB650_Data: server-com-spec{operation=ReadData, queue-length=1}, provided-interface=DataServices_RDB650_Data
      DataServices_RDB651_Data: server-com-spec{operation=ReadData, queue-length=1}, provided-interface=DataServices_RDB651_Data
      DataServices_RDB{653..655}_Data: server-com-spec{operation=ReadData, queue-length=1}, provided-interface=DataServices_RDB{653..655}_Data
      DataServices_RDB779_Data: server-com-spec{operation=ReadData, queue-length=1}, provided-interface=DataServices_RDB779_Data
      DataServices_RDB789_Data: server-com-spec{operation=ReadData, queue-length=1}, provided-interface=DataServices_RDB789_Data
      DataServices_RWD2800_Data: provided-com-specs=[{operation=ReadData, queue-length=1}, {operation=WriteData, queue-length=1}], provided-interface=DataServices_RWD2800_Data
      DataServices_RWD3025_Data: provided-com-specs=[{operation=ReadData, queue-length=1}, {operation=WriteData, queue-length=1}], provided-interface=DataServices_RWD3025_Data
      DataServices_RWD3029_Data: provided-com-specs=[{operation=ReadData, queue-length=1}, {operation=WriteData, queue-length=1}], provided-interface=DataServices_RWD3029_Data
      DataServices_RWD3202_Data: provided-com-specs=[{operation=ReadData, queue-length=1}, {operation=WriteData, queue-length=1}], provided-interface=DataServices_RWD3202_Data
      DataServices_RWD9E15_Data: provided-com-specs=[{operation=ReadData, queue-length=1}, {operation=WriteData, queue-length=1}], provided-interface=DataServices_RWD9E15_Data
      DataServices_RWD9E{20..23}_Data: provided-com-specs=[{operation=ReadData, queue-length=1}, {operation=WriteData, queue-length=1}], provided-interface=DataServices_RWD9E{20..23}_Data
      DataServices_RWD9E3B_Data: provided-com-specs=[{operation=ReadData, queue-length=1}, {operation=WriteData, queue-length=1}], provided-interface=DataServices_RWD9E3B_Data
      DataServices_RWD9EEB_Data: provided-com-specs=[{operation=ReadData, queue-length=1}, {operation=WriteData, queue-length=1}], provided-interface=DataServices_RWD9EEB_Data
      DataServices_RWD9EEC_Data: provided-com-specs=[{operation=ReadData, queue-length=1}, {operation=WriteData, queue-length=1}], provided-interface=DataServices_RWD9EEC_Data
      DataServices_RWDB604_Data: provided-com-specs=[{operation=ReadData, queue-length=1}, {operation=WriteData, queue-length=1}], provided-interface=DataServices_RWDB604_Data
      DataServices_RWDB607_Data: provided-com-specs=[{operation=ReadData, queue-length=1}, {operation=WriteData, queue-length=1}], provided-interface=DataServices_RWDB607_Data
      DataServices_RWDB61B_Data: provided-com-specs=[{operation=ReadData, queue-length=1}, {operation=WriteData, queue-length=1}], provided-interface=DataServices_RWDB61B_Data
      DataServices_RWDB62F_Data: provided-com-specs=[{operation=ReadData, queue-length=1}, {operation=WriteData, queue-length=1}], provided-interface=DataServices_RWDB62F_Data
      DataServices_RWDB652_Data: provided-com-specs=[{operation=ReadData, queue-length=1}, {operation=WriteData, queue-length=1}], provided-interface=DataServices_RWDB652_Data
      RoutineServices_RC1300: server-com-spec{operation=Start, queue-length=1}, provided-interface=RoutineServices_RC1300
      RoutineServices_RC1303: provided-interface=RoutineServices_RC1303
        provided-com-specs:
          operation=RequestResults, queue-length=1
          operation=Start, queue-length=1
          operation=Stop, queue-length=1
      RoutineServices_RC1309: provided-com-specs=[{operation=RequestResults, queue-length=1}, {operation=Start, queue-length=1}], provided-interface=RoutineServices_RC1309
      RoutineServices_RC130B: server-com-spec{operation=Start, queue-length=1}, provided-interface=RoutineServices_RC130B
      RoutineServices_RC130C: provided-interface=RoutineServices_RC130C
        provided-com-specs:
          operation=RequestResults, queue-length=1
          operation=Start, queue-length=1
          operation=Stop, queue-length=1
      RoutineServices_RC130D: provided-interface=RoutineServices_RC130D
        provided-com-specs:
          operation=RequestResults, queue-length=1
          operation=Start, queue-length=1
          operation=Stop, queue-length=1
      RoutineServices_RC130E: provided-com-specs=[{operation=RequestResults, queue-length=1}, {operation=Start, queue-length=1}], provided-interface=RoutineServices_RC130E
      RoutineServices_RC130F: provided-com-specs=[{operation=RequestResults, queue-length=1}, {operation=Start, queue-length=1}], provided-interface=RoutineServices_RC130F
      RoutineServices_RC1313: provided-interface=RoutineServices_RC1313
        provided-com-specs:
          operation=RequestResults, queue-length=1
          operation=Start, queue-length=1
          operation=Stop, queue-length=1
      RoutineServices_RC1314: provided-interface=RoutineServices_RC1314
        provided-com-specs:
          operation=RequestResults, queue-length=1
          operation=Start, queue-length=1
          operation=Stop, queue-length=1
      RoutineServices_RC1330: provided-interface=RoutineServices_RC1330
        provided-com-specs:
          operation=RequestResults, queue-length=1
          operation=Start, queue-length=1
          operation=Stop, queue-length=1
      RoutineServices_RC1332: provided-interface=RoutineServices_RC1332
        provided-com-specs:
          operation=RequestResults, queue-length=1
          operation=Start, queue-length=1
          operation=Stop, queue-length=1
      RoutineServices_RC1333: provided-interface=RoutineServices_RC1333
        provided-com-specs:
          operation=RequestResults, queue-length=1
          operation=Start, queue-length=1
          operation=Stop, queue-length=1
      RoutineServices_RC1336: provided-com-specs=[{operation=RequestResults, queue-length=1}, {operation=Start, queue-length=1}], provided-interface=RoutineServices_RC1336
